CM_ "AUTOGENERATED FILE, DO NOT EDIT";

CM_ "hyundai_canfd.dbc starts here";
VERSION ""

NS_ :

BS_:

BU_: XXX CAMERA FRONT_RADAR ADRV APRK

BO_ 53 ACCELERATOR: 32 XXX
 SG_ CHECKSUM : 0|16@1+ (1,0) [0|65535] "" XXX
 SG_ COUNTER : 16|8@1+ (1,0) [0|255] "" XXX
 SG_ ACCELERATOR_PEDAL : 40|8@1+ (1,0) [0|255] "" XXX
 SG_ GEAR : 192|3@1+ (1,0) [0|7] "" XXX

BO_ 64 GEAR_ALT: 32 XXX
 SG_ CHECKSUM : 0|16@1+ (1,0) [0|65535] "" XXX
 SG_ COUNTER : 16|8@1+ (1,0) [0|255] "" XXX
 SG_ GEAR : 32|3@1+ (1,0) [0|7] "" XXX
 SG_ GEAR_STEP : 67|4@0+ (1,0) [0|15] "" XXX
 SG_ NEW_SIGNAL_4 : 68|4@1+ (1,0) [0|15] "" XXX
 SG_ NEW_SIGNAL_1 : 75|4@0+ (1,0) [0|15] "" XXX
 SG_ NEW_SIGNAL_3 : 76|4@1+ (1,0) [0|15] "" XXX

BO_ 69 GEAR: 24 XXX
 SG_ CHECKSUM : 0|16@1+ (1,0) [0|65535] "" XXX
 SG_ COUNTER : 16|8@1+ (1,0) [0|255] "" XXX
 SG_ GEAR : 44|3@1+ (1,0) [0|7] "" XXX
 SG_ RIGHT_PADDLE : 57|1@0+ (1,0) [0|1] "" XXX
 SG_ LEFT_PADDLE : 58|1@0+ (1,0) [0|1] "" XXX
 SG_ GEAR_STEP : 146|5@1+ (1,0) [0|31] "" XXX
 SG_ GEAR_STEP1 : 154|5@1+ (1,0) [0|31] "" XXX

BO_ 80 LKAS: 16 XXX
 SG_ CHECKSUM : 0|16@1+ (1,0) [0|65535] "" XXX
 SG_ COUNTER : 16|8@1+ (1,0) [0|255] "" XXX
 SG_ LKA_MODE : 24|3@1+ (1,0) [0|7] "" XXX
 SG_ LKA_ACTIVE : 27|2@1+ (1,0) [0|255] "" XXX
 SG_ LKA_WARNING : 32|1@1+ (1,0) [0|1] "" XXX
 SG_ LKA_ICON : 38|2@1+ (1,0) [0|255] "" XXX
 SG_ FCA_SYSWARN : 40|1@0+ (1,0) [0|1] "" XXX
 SG_ TORQUE_REQUEST : 41|11@1+ (1,-1024) [0|4095] "" XXX
 SG_ STEER_REQ : 52|1@1+ (1,0) [0|1] "" XXX
 SG_ LFA_BUTTON : 56|1@1+ (1,0) [0|255] "" XXX
 SG_ VALUE63 : 63|4@0+ (1,0) [0|15] "" XXX
 SG_ VALUE64 : 64|8@1+ (1,0) [0|255] "" XXX
 SG_ NEW_SIGNAL_1 : 75|4@0+ (1,0) [0|15] "" XXX
 SG_ LKAS_ANGLE_ACTIVE : 77|2@0+ (1,0) [0|3] "" XXX
 SG_ HAS_LANE_SAFETY : 80|1@0+ (1,0) [0|1] "" XXX
 SG_ LKAS_ANGLE_CMD : 82|14@1- (-0.1,0) [0|511] "" XXX
 SG_ LKAS_ANGLE_MAX_TORQUE : 96|8@1+ (1,0) [0|255] "" XXX
 SG_ DampingGain : 104|8@1+ (1,0) [0|255] "" XXX

BO_ 81 ADRV_0x51: 32 ADRV
 SG_ CHECKSUM : 0|16@1+ (1,0) [0|65535] "" XXX
 SG_ COUNTER : 16|8@1+ (1,0) [0|255] "" XXX

BO_ 96 ESP_STATUS: 32 XXX
 SG_ CHECKSUM : 0|16@1+ (1,0) [0|65535] "" XXX
 SG_ COUNTER : 16|8@1+ (1,0) [0|255] "" XXX
 SG_ TRACTION_AND_STABILITY_CONTROL : 42|3@1+ (1,0) [0|63] "" XXX
 SG_ BRAKE_PRESSURE : 128|11@1+ (1,0) [0|2047] "" XXX
 SG_ BRAKE_PRESSED : 148|1@1+ (1,0) [0|3] "" XXX
 SG_ AVH_Sta : 192|2@1+ (1,0) [0|3] "" XXX
 SG_ AVH_I_LAMP : 218|2@1+ (1,0) [0|3] "" XXX
 SG_ AVH_LAMP : 220|3@1+ (1,0) [0|7] "" XXX

BO_ 101 BRAKE: 32 XXX
 SG_ CHECKSUM : 0|16@1+ (1,0) [0|65535] "" XXX
 SG_ COUNTER : 16|8@1+ (1,0) [0|255] "" XXX
 SG_ BRAKE_LIGHT : 29|1@0+ (1,0) [0|1] "" XXX
 SG_ BRAKE_POSITION : 40|16@1- (1,0) [0|65535] "" XXX
 SG_ BRAKE_PRESSED : 57|1@1+ (1,0) [0|3] "" XXX

BO_ 112 GEAR_ALT_2: 32 XXX
 SG_ CHECKSUM : 0|16@1+ (1,0) [0|65535] "" XXX
 SG_ COUNTER : 16|8@1+ (1,0) [0|255] "" XXX
 SG_ GEAR : 60|3@1+ (1,0) [0|7] "" XXX

BO_ 147 CANFD_NAVI_PROFILE_093: 24 XXX
 SG_ PROLONG_VALUE : 64|32@1+ (1,0) [0|4294967295] "" XXX
 SG_ PROLONG_OFFSET : 96|13@1+ (1,0) [0|8191] "m" XXX
 SG_ PROLONG_CYCLIC_COUNTER : 109|2@1+ (1,0) [0|3] "" XXX
 SG_ PROLONG_UPDATE : 111|1@1+ (1,0) [0|1] "" XXX
 SG_ PROLONG_PATH_INDEX : 112|6@1+ (1,0) [0|63] "" XXX
 SG_ PROLONG_PROFILE_TYPE : 118|5@1+ (1,0) [0|31] "" XXX

BO_ 160 WHEEL_SPEEDS: 24 XXX
 SG_ CHECKSUM : 0|16@1+ (1,0) [0|65535] "" XXX
 SG_ COUNTER : 16|8@1+ (1,0) [0|255] "" XXX
 SG_ MOVING_FORWARD : 56|1@0+ (1,0) [0|1] "" XXX
 SG_ MOVING_BACKWARD : 57|1@0+ (1,0) [0|1] "" XXX
 SG_ MOVING_FORWARD2 : 58|1@0+ (1,0) [0|1] "" XXX
 SG_ MOVING_BACKWARD2 : 59|1@0+ (1,0) [0|1] "" XXX
 SG_ WHEEL_SPEED_1 : 64|16@1+ (0.03125,0) [0|65535] "kph" XXX
 SG_ WHEEL_SPEED_2 : 80|16@1+ (0.03125,0) [0|65535] "kph" XXX
 SG_ WHEEL_SPEED_3 : 96|16@1+ (0.03125,0) [0|65535] "kph" XXX
 SG_ WHEEL_SPEED_4 : 112|16@1+ (0.03125,0) [0|65535] "kph" XXX

BO_ 203 LFA_ALT: 24 ADRV
 SG_ CHECKSUM : 0|16@1+ (1,0) [0|65535] "" XXX
 SG_ COUNTER : 16|8@1+ (1,0) [0|255] "" XXX
 SG_ LKAS_ANGLE_ACTIVE : 29|2@0+ (1,0) [0|3] "" XXX
 SG_ LKAS_ANGLE_CMD : 32|14@1- (-0.1,0) [0|511] "" XXX
 SG_ LKAS_ANGLE_MAX_TORQUE : 55|8@0+ (1,0) [0|255] "" XXX

BO_ 234 MDPS: 24 XXX
 SG_ CHECKSUM : 0|16@1+ (1,0) [0|65535] "" XXX
 SG_ COUNTER : 16|8@1+ (1,0) [0|255] "" XXX
 SG_ NEW_SIGNAL_1 : 31|8@0+ (1,0) [0|255] "" XXX
 SG_ NEW_SIGNAL_2 : 39|8@0+ (1,0) [0|255] "" XXX
 SG_ NEW_SIGNAL_3 : 47|8@0+ (1,0) [0|255] "" XXX
 SG_ LKA_ACTIVE : 48|1@0+ (1,0) [0|16777215] "" XXX
 SG_ LKA_FAULT : 54|1@0+ (1,0) [0|1] "" XXX
 SG_ STEERING_OUT_TORQUE : 64|12@1+ (0.1,-204.8) [0|65535] "" XXX
 SG_ STEERING_COL_TORQUE : 80|13@1+ (1,-4095) [0|4095] "" XXX
 SG_ STEERING_ANGLE : 96|16@1- (-0.1,0) [0|255] "deg" XXX
 SG_ STEERING_ANGLE_2 : 128|16@1- (-0.1,0) [0|65535] "deg" XXX
 SG_ LFA2_ACTIVE : 145|2@0+ (1,0) [0|3] "" XXX
 SG_ LFA2_FAULT : 149|1@0+ (1,0) [0|1] "" XXX
 SG_ NEW_SIGNAL_4 : 159|8@0+ (1,0) [0|255] "" XXX
 SG_ NEW_SIGNAL_5 : 167|8@0+ (1,0) [0|255] "" XXX
 SG_ NEW_SIGNAL_6 : 175|8@0+ (1,0) [0|255] "" XXX

BO_ 256 ACCELERATOR_BRAKE_ALT: 32 XXX
 SG_ CHECKSUM : 0|16@1+ (1,0) [0|65535] "" XXX
 SG_ COUNTER : 16|8@1+ (1,0) [0|255] "" XXX
 SG_ BRAKE_PRESSED : 32|1@1+ (1,0) [0|1] "" XXX
 SG_ ACCELERATOR_PEDAL_PRESSED : 176|1@1+ (1,0) [0|1] "" XXX

BO_ 261 ACCELERATOR_ALT: 32 XXX
 SG_ CHECKSUM : 0|16@1+ (1,0) [0|65535] "" XXX
 SG_ COUNTER : 16|8@1+ (1,0) [0|255] "" XXX
 SG_ ACCELERATOR_PEDAL : 103|10@1+ (0.25,0) [0|1022] "" XXX

BO_ 267 CRUISE_BUTTONS_ALT2: 16 XXX
 SG_ CRUISE_BUTTONS : 83|4@0+ (1,0) [0|15] "" XXX
 SG_ LFA_BTN : 87|1@0+ (1,0) [0|1] "" XXX

BO_ 272 LKAS_ALT: 32 XXX
 SG_ CHECKSUM : 0|16@1+ (1,0) [0|65535] "" XXX
 SG_ COUNTER : 16|8@1+ (1,0) [0|255] "" XXX
 SG_ LKA_MODE : 24|3@1+ (1,0) [0|7] "" XXX
 SG_ LKA_ACTIVE : 27|2@1+ (1,0) [0|3] "" XXX
 SG_ LKA_WARNING : 32|1@1+ (1,0) [0|1] "" XXX
 SG_ LKA_ICON : 38|2@1+ (1,0) [0|3] "" XXX
 SG_ FCA_SYSWARN : 40|1@0+ (1,0) [0|1] "" XXX
 SG_ TORQUE_REQUEST : 41|11@1+ (1,-1024) [0|4095] "" XXX
 SG_ STEER_REQ : 52|1@1+ (1,0) [0|1] "" XXX
 SG_ LFA_BUTTON : 56|1@1+ (1,0) [0|1] "" XXX
 SG_ VALUE63 : 63|4@0+ (1,0) [0|15] "" XXX
 SG_ VALUE64 : 64|8@1+ (1,0) [0|255] "" XXX
 SG_ NEW_SIGNAL_1 : 75|4@0+ (1,0) [0|15] "" XXX
 SG_ LKAS_ANGLE_ACTIVE : 77|2@0+ (1,0) [0|3] "" XXX
 SG_ HAS_LANE_SAFETY : 80|1@0+ (1,0) [0|1] "" XXX
 SG_ LKAS_ANGLE_CMD : 82|14@1- (-0.1,0) [0|511] "" XXX
 SG_ LKAS_ANGLE_MAX_TORQUE : 96|8@1+ (1,0) [0|255] "" XXX
 SG_ DampingGain : 104|8@1+ (1,0) [0|255] "" XXX
 SG_ VALUE231 : 231|8@0+ (1,0) [0|255] "" XXX
 SG_ VALUE239 : 239|8@0+ (1,0) [0|255] "" XXX
 SG_ VALUE247 : 247|8@0+ (1,0) [0|255] "" XXX
 SG_ VALUE255 : 255|8@0+ (1,0) [0|255] "" XXX

BO_ 293 STEERING_SENSORS: 16 XXX
 SG_ CHECKSUM : 0|16@1+ (1,0) [0|65535] "" XXX
 SG_ COUNTER : 16|8@1+ (1,0) [0|255] "" XXX
 SG_ STEERING_ANGLE : 24|16@1- (-0.1,0) [0|255] "deg" XXX
 SG_ STEERING_RATE : 40|8@1+ (4,0) [0|1016] "deg/s" XXX

BO_ 298 LFA: 16 ADRV
 SG_ CHECKSUM : 0|16@1+ (1,0) [0|65535] "" XXX
 SG_ COUNTER : 16|8@1+ (1,0) [0|255] "" XXX
 SG_ LKA_MODE : 24|3@1+ (1,0) [0|7] "" XXX
 SG_ LKA_ACTIVE : 27|2@1+ (1,0) [0|3] "" XXX
 SG_ LKA_WARNING : 32|1@1+ (1,0) [0|1] "" XXX
 SG_ LKA_ICON : 38|2@1+ (1,0) [0|3] "" XXX
 SG_ FCA_SYSWARN : 40|1@0+ (1,0) [0|1] "" XXX
 SG_ TORQUE_REQUEST : 41|11@1+ (1,-1024) [0|4095] "" XXX
 SG_ STEER_REQ : 52|1@1+ (1,0) [0|1] "" XXX
 SG_ LFA_BUTTON : 56|1@1+ (1,0) [0|1] "" XXX
 SG_ VALUE63 : 63|4@0+ (1,0) [0|15] "" XXX
 SG_ VALUE64 : 64|8@1+ (1,0) [0|255] "" XXX
 SG_ NEW_SIGNAL_1 : 75|4@0+ (1,0) [0|15] "" XXX
 SG_ LKAS_ANGLE_ACTIVE : 77|2@0+ (1,0) [0|3] "" XXX
 SG_ HAS_LANE_SAFETY : 80|1@0+ (1,0) [0|1] "" XXX
 SG_ LKAS_ANGLE_CMD : 82|14@1- (-0.1,0) [0|511] "" XXX
 SG_ LKAS_ANGLE_MAX_TORQUE : 96|8@1+ (1,0) [0|255] "" XXX
 SG_ DampingGain : 104|8@1+ (1,0) [0|255] "" XXX
 SG_ VALUE231 : 231|8@0+ (1,0) [0|255] "" XXX
 SG_ VALUE239 : 239|8@0+ (1,0) [0|255] "" XXX
 SG_ VALUE247 : 247|8@0+ (1,0) [0|255] "" XXX
 SG_ VALUE255 : 255|8@0+ (1,0) [0|255] "" XXX

BO_ 304 GEAR_SHIFTER: 16 XXX
 SG_ CHECKSUM : 0|16@1+ (1,0) [0|65535] "" XXX
 SG_ COUNTER : 16|8@1+ (1,0) [0|255] "" XXX
 SG_ PARK_BUTTON : 32|2@1+ (1,0) [0|3] "" XXX
 SG_ KNOB_POSITION : 40|3@1+ (1,0) [0|3] "" XXX
 SG_ GEAR : 64|3@1+ (1,0) [0|7] "" XXX

BO_ 1079 TRAILER_STATUS: 8 XXX
 SG_ TRAILER_CONNECTED : 0|1@1+ (1,0) [0|1] "" XXX

BO_ 352 ADRV_0x160: 16 ADRV
 SG_ CHECKSUM : 0|16@1+ (1,0) [0|65535] "" XXX
 SG_ COUNTER : 16|8@1+ (1,0) [0|255] "" XXX
 SG_ AEB_SETTING : 24|2@1+ (1,0) [0|255] "" XXX
 SG_ NEW_SIGNAL_1 : 30|1@0+ (1,0) [0|1] "" XXX
 SG_ NEW_SIGNAL_4 : 31|1@0+ (1,0) [0|1] "" XXX
 SG_ NEW_SIGNAL_5 : 39|8@0+ (1,0) [0|255] "" XXX
 SG_ NEW_SIGNAL_6 : 47|8@0+ (1,0) [0|255] "" XXX
 SG_ NEW_SIGNAL_2 : 55|8@0+ (1,0) [0|255] "" XXX
 SG_ SET_ME_2 : 56|8@1+ (1,0) [0|1] "" XXX
 SG_ SET_ME_FF : 64|8@1+ (1,0) [0|255] "" XXX
 SG_ SET_ME_FC : 72|8@1+ (1,0) [0|255] "" XXX
 SG_ SET_ME_9 : 80|8@1+ (1,0) [0|255] "" XXX
 SG_ NEW_SIGNAL_3 : 95|8@0+ (1,0) [0|255] "" XXX
 SG_ NEW_SIGNAL_7 : 102|1@0+ (1,0) [0|1] "" XXX

BO_ 353 ADRV_0x161: 32 ADRV
 SG_ CHECKSUM : 0|16@1+ (1,0) [0|65535] "" XXX
 SG_ COUNTER : 16|8@1+ (1,0) [0|255] "" XXX
 SG_ FCA_ICON : 24|3@1+ (1,0) [0|7] "" XXX
 SG_ FCA_ALT_ICON : 27|3@1+ (1,0) [0|7] "" XXX
 SG_ LKA_ICON : 30|3@1+ (1,0) [0|3] "" XXX
 SG_ HBA_ICON : 33|3@1+ (1,0) [0|7] "" XXX
 SG_ FCA_IMAGE : 42|3@1+ (1,0) [0|7] "" XXX
 SG_ BCA_LEFT : 51|3@1+ (1,0) [0|7] "" XXX
 SG_ BCA_RIGHT : 54|3@1+ (1,0) [0|7] "" XXX
 SG_ LCA_LEFT_ARROW : 57|3@1+ (1,0) [0|7] "" XXX
 SG_ LCA_RIGHT_ARROW : 60|3@1+ (1,0) [0|7] "" XXX
 SG_ CENTERLINE : 64|2@1+ (1,0) [0|3] "" XXX
 SG_ TARGET : 66|3@1+ (1,0) [0|7] "" XXX
 SG_ TARGET_DISTANCE : 69|11@1+ (0.1,0) [0|204.7] "m" XXX
 SG_ LANELINE_LEFT : 80|4@1+ (1,0) [0|15] "" XXX
 SG_ LANELINE_LEFT_POSITION : 84|6@1+ (1,0) [0|15] "" XXX
 SG_ LANELINE_RIGHT : 90|4@1+ (1,0) [0|15] "" XXX
 SG_ LANELINE_RIGHT_POSITION : 94|6@1+ (1,0) [0|15] "" XXX
 SG_ LANELINE_CURVATURE : 100|4@1+ (1,0) [0|31] "" XXX
 SG_ LANELINE_CURVATURE_DIRECTION : 104|1@0+ (1,0) [0|1] "" XXX
 SG_ LANE_HIGHLIGHT : 105|4@1+ (1,0) [0|15] "" XXX
 SG_ LANE_HIGHLIGHT_DISTANCE : 109|11@1+ (0.1,0) [0|204.7] "m" XXX
 SG_ LANE_LEFT : 120|3@1+ (1,0) [0|7] "" XXX
 SG_ LANE_RIGHT : 123|3@1+ (1,0) [0|7] "" XXX
 SG_ LANE_ZOOM : 126|2@1+ (1,0) [0|3] "" XXX
 SG_ ALERTS_1 : 128|6@1+ (1,0) [0|63] "" XXX
 SG_ ALERTS_2 : 134|5@1+ (1,0) [0|31] "" XXX
 SG_ ALERTS_3 : 139|5@1+ (1,0) [0|31] "" XXX
 SG_ ALERTS_4 : 144|8@1+ (1,0) [0|255] "" XXX
 SG_ ALERTS_5 : 152|5@1+ (1,0) [0|31] "" XXX
 SG_ MUTE : 157|3@1+ (1,0) [0|7] "" XXX
 SG_ SOUNDS_1 : 160|4@1+ (1,0) [0|3] "" XXX
 SG_ SOUNDS_2 : 164|4@1+ (1,0) [0|3] "" XXX
 SG_ SOUNDS_3 : 168|4@1+ (1,0) [0|15] "" XXX
 SG_ SOUNDS_4 : 172|3@1+ (1,0) [0|7] "" XXX
 SG_ SETSPEED_HUD : 181|3@1+ (1,0) [0|7] "" XXX
 SG_ DISTANCE_LEAD : 184|5@1+ (1,0) [0|31] "" XXX
 SG_ DISTANCE_CAR : 189|3@1+ (1,0) [0|7] "" XXX
 SG_ DISTANCE_SPACING : 192|4@1+ (1,0) [0|15] "" XXX
 SG_ DISTANCE : 196|4@1+ (1,0) [0|7] "" XXX
 SG_ vSetDis : 200|8@1+ (1,0) [0|255] "" XXX
 SG_ SETSPEED : 208|4@1+ (1,0) [0|7] "" XXX
 SG_ HDA_ICON : 212|3@1+ (1,0) [0|7] "" XXX
 SG_ SLA_ICON : 216|4@1+ (1,0) [0|15] "" XXX
 SG_ NAV_ICON : 220|3@1+ (1,0) [0|7] "" XXX
 SG_ LFA_ICON : 224|3@1+ (1,0) [0|7] "" XXX
 SG_ LCA_LEFT_ICON : 228|3@1+ (1,0) [0|7] "" XXX
 SG_ LCA_RIGHT_ICON : 232|3@1+ (1,0) [0|7] "" XXX
 SG_ BACKGROUND : 236|4@1+ (1,0) [0|15] "" XXX
 SG_ DAW_ICON : 240|3@1+ (1,0) [0|7] "" XXX
 SG_ CAR_CIRCLE : 243|3@1+ (1,0) [0|7] "" XXX

BO_ 354 CCNC_0x162: 32 CCNC
 SG_ CHECKSUM : 0|16@1+ (1,0) [0|65535] "" XXX
 SG_ COUNTER : 16|8@1+ (1,0) [0|255] "" XXX
 SG_ COUNTRY : 24|4@1+ (1,0) [0|7] "" XXX
 SG_ SPEEDLIMIT_FLASH : 28|4@1+ (1,0) [0|15] "" XXX
 SG_ SPEEDLIMIT : 32|8@1+ (1,0) [0|255] "" XXX
 SG_ SIGNS : 40|8@1+ (1,0) [0|15] "" XXX
 SG_ SPEEDLIMIT_WEATHER : 48|4@1+ (1,0) [0|15] "" XXX
 SG_ VIBRATE : 52|1@0+ (1,0) [0|1] "" XXX
 SG_ FF_DETECT : 64|5@1+ (1,0) [0|31] "" XXX
 SG_ FF_DISTANCE : 69|11@1+ (0.1,0) [0|204.7] "m" XXX
 SG_ FF_LATERAL : 80|7@1+ (0.1,0) [0|127] "m" XXX
 SG_ FF_DETECT_ALT : 88|5@1+ (1,0) [0|31] "" XXX
 SG_ FF_DISTANCE_ALT : 93|11@1+ (0.1,0) [0|204.7] "m" XXX
 SG_ FF_LATERAL_ALT : 104|7@1+ (0.1,0) [0|127] "m" XXX
 SG_ LF_DETECT : 112|5@1+ (1,0) [0|31] "" XXX
 SG_ LF_DETECT_DISTANCE : 117|11@1+ (0.1,0) [0|204.7] "m" XXX
 SG_ LF_DETECT_LATERAL : 128|7@1+ (0.1,0) [0|127] "m" XXX
 SG_ RF_DETECT : 136|5@1+ (1,0) [0|31] "" XXX
 SG_ RF_DETECT_DISTANCE : 141|11@1+ (0.1,0) [0|204.7] "m" XXX
 SG_ RF_DETECT_LATERAL : 152|7@1+ (0.1,0) [0|127] "m" XXX
 SG_ LR_DETECT : 163|5@1+ (1,0) [0|31] "" XXX
 SG_ LR_DETECT_DISTANCE : 175|8@0+ (0.1,0) [0|255] "" XXX
 SG_ LR_DETECT_LATERAL : 176|7@1+ (0.1,0) [0|127] "" XXX
 SG_ RR_DETECT : 192|5@1+ (1,0) [0|31] "" XXX
 SG_ RR_DETECT_DISTANCE : 197|8@1+ (0.1,0) [0|255] "" XXX
 SG_ RR_DETECT_LATERAL : 205|7@1+ (0.1,0) [0|127] "" XXX
 SG_ FAULT_FSS : 213|3@1+ (1,0) [0|7] "" XXX
 SG_ FAULT_FCA : 216|3@1+ (1,0) [0|7] "" XXX
 SG_ FAULT_LSS : 219|3@1+ (1,0) [0|7] "" XXX
 SG_ FAULT_SLA : 222|3@1+ (1,0) [0|7] "" XXX
 SG_ FAULT_DAW : 225|3@1+ (1,0) [0|7] "" XXX
 SG_ FAULT_HBA : 228|3@1+ (1,0) [0|7] "" XXX
 SG_ FAULT_SCC : 231|3@1+ (1,0) [0|7] "" XXX
 SG_ FAULT_LFA : 234|3@1+ (1,0) [0|7] "" XXX
 SG_ FAULT_HDA : 237|3@1+ (1,0) [0|7] "" XXX
 SG_ FAULT_LCA : 240|3@1+ (1,0) [0|7] "" XXX
 SG_ FAULT_HDP : 243|3@1+ (1,0) [0|7] "" XXX
 SG_ FAULT_DAS : 246|3@1+ (1,0) [0|7] "" XXX
 SG_ FAULT_ESS : 249|3@1+ (1,0) [0|7] "" XXX

BO_ 357 SPAS1: 24 APRK
 SG_ CHECKSUM : 0|16@1+ (1,0) [0|65535] "" XXX
 SG_ COUNTER : 16|8@1+ (1,0) [0|0] "" XXX
 SG_ NEW_SIGNAL_2 : 90|3@1+ (1,0) [0|0] "" XXX
 SG_ NEW_SIGNAL_1 : 96|16@1- (0.1,0) [0|0] "" XXX

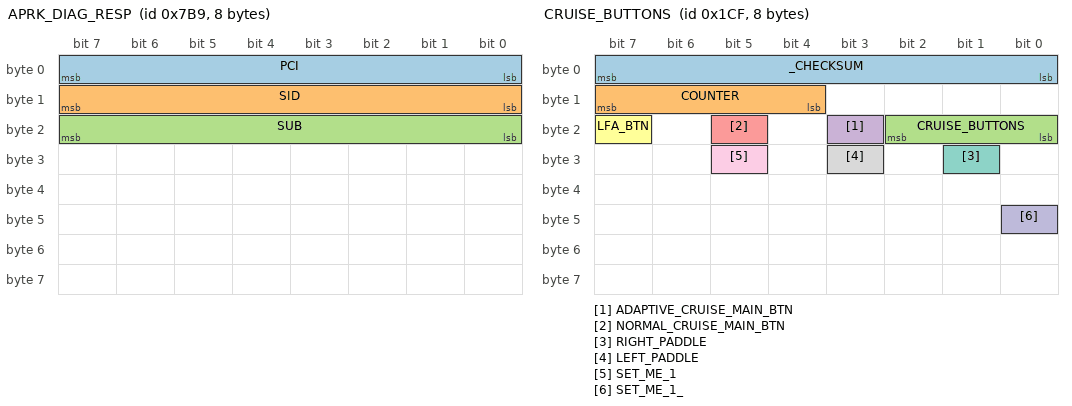
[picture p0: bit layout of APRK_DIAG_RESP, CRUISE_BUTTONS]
BO_ 1977 APRK_DIAG_RESP: 8 APRK
 SG_ PCI : 0|8@1+ (1,0) [0|255] "" XXX
 SG_ SID : 8|8@1+ (1,0) [0|255] "" XXX
 SG_ SUB : 16|8@1+ (1,0) [0|255] "" XXX

BO_ 1024 SVM_STATUS_400: 8 XXX
 SG_ BYTE3 : 24|8@1+ (1,0) [0|255] "" XXX
 SG_ BVM_VIEW : 32|8@1+ (1,0) [0|255] "" XXX

BO_ 362 SPAS2: 32 APRK
 SG_ CHECKSUM : 0|16@1+ (1,0) [0|65535] "" XXX
 SG_ COUNTER : 16|8@1+ (1,0) [0|0] "" XXX
 SG_ BLINKER_CONTROL : 133|3@1+ (1,0) [0|0] "" XXX
 SG_ BYTE3 : 24|8@1+ (1,0) [0|255] "" XXX
 SG_ BYTE4 : 32|8@1+ (1,0) [0|255] "" XXX
 SG_ BYTE10 : 80|8@1+ (1,0) [0|255] "" XXX
 SG_ BYTE11 : 88|8@1+ (1,0) [0|255] "" XXX
 SG_ BYTE12 : 96|8@1+ (1,0) [0|255] "" XXX
 SG_ BYTE13 : 104|8@1+ (1,0) [0|255] "" XXX
 SG_ BYTE14 : 112|8@1+ (1,0) [0|255] "" XXX
 SG_ BYTE15 : 120|8@1+ (1,0) [0|255] "" XXX
 SG_ BYTE20 : 160|8@1+ (1,0) [0|255] "" XXX

BO_ 373 TCS: 24 XXX
 SG_ CHECKSUM : 0|16@1+ (1,0) [0|65535] "" XXX
 SG_ COUNTER : 16|8@1+ (1,0) [0|255] "" XXX
 SG_ NEW_SIGNAL_4 : 24|7@1+ (1,0) [0|127] "" XXX
 SG_ NEW_SIGNAL_9 : 31|1@0+ (1,0) [0|1] "" XXX
 SG_ aBasis : 32|11@1+ (0.01,-10.23) [0|7] "m/s^2" XXX
 SG_ NEW_SIGNAL_1 : 47|5@0+ (1,0) [0|31] "" XXX
 SG_ ACCEL_REF_ACC : 48|11@1- (1,0) [0|1023] "" XXX
 SG_ NEW_SIGNAL_2 : 63|5@0+ (1,0) [0|31] "" XXX
 SG_ SCC_OptTyp : 64|2@1+ (1,0) [0|0] "" AWD,EMS,FR_CMR,HCU,H_U_MM,TCU,VCU,vBDM
 SG_ ACCEnable : 67|2@0+ (1,0) [0|3] "" XXX
 SG_ ACC_REQ : 68|1@0+ (1,0) [0|1] "" XXX
 SG_ NEW_SIGNAL_3 : 69|1@0+ (1,0) [0|1] "" XXX
 SG_ SCC_ReqLimSta : 70|2@1+ (1,0) [0|0] "" ADAS_DRV,AWD,Dummy,EMS,FR_CMR,H_U_MM,TCU,vBDM
 SG_ ESC_StdStillVal : 72|2@1+ (1,0) [0|3] "" ADAS_DRV,AWD,Dummy,EMS,FR_CMR,H_U_MM,TCU,vBDM
 SG_ BrakeLight : 74|2@1+ (1,0) [0|3] "" XXX
 SG_ ESC_DclEnblReq : 76|2@1+ (1,0) [0|3] "" AWD,Dummy,EMS,FR_CMR,H_U_MM,TCU,vBDM
 SG_ NEW_SIGNAL_5 : 79|2@0+ (1,0) [0|3] "" XXX
 SG_ NEW_SIGNAL_21 : 80|1@0+ (1,0) [0|1] "" XXX
 SG_ DriverBraking : 81|1@0+ (1,0) [0|1] "" XXX
 SG_ NEW_SIGNAL_20 : 82|1@0+ (1,0) [0|1] "" XXX
 SG_ NEW_SIGNAL_11 : 83|1@0+ (1,0) [0|1] "" XXX
 SG_ DriverBrakingLowSens : 84|1@1+ (1,0) [0|1] "" XXX
 SG_ NEW_SIGNAL_10 : 85|1@0+ (1,0) [0|1] "" XXX
 SG_ ESC_PrkBrkActvSta : 86|2@1+ (1,0) [0|3] "" ADAS_DRV,AWD,Dummy,EMS,FR_CMR,H_U_MM,RR_C_RDR,TCU,vBDM
 SG_ NEW_SIGNAL_12 : 95|8@0+ (1,0) [0|255] "" XXX
 SG_ FCA_EquipSta : 96|2@1+ (1,0) [0|3] "" ADAS_DRV,FR_CMR,H_U_MM,vBDM
 SG_ FCA_AvlblSta : 98|2@1+ (1,0) [0|3] "" ADAS_DRV,AFCU_DRV,CLU,Dummy,FR_CMR,H_U_MM,vBDM
 SG_ NEW_SIGNAL_13 : 103|4@0+ (1,0) [0|15] "" XXX
 SG_ NEW_SIGNAL_14 : 111|8@0+ (1,0) [0|255] "" XXX
 SG_ NEW_SIGNAL_15 : 119|8@0+ (1,0) [0|255] "" XXX
 SG_ NEW_SIGNAL_16 : 127|8@0+ (1,0) [0|255] "" XXX
 SG_ NEW_SIGNAL_6 : 128|4@1+ (1,0) [0|15] "" XXX
 SG_ NEW_SIGNAL_17 : 133|2@0+ (1,0) [0|3] "" XXX
 SG_ NEW_SIGNAL_7 : 135|2@0+ (1,0) [0|3] "" XXX
 SG_ PROBABLY_EQUIP : 136|2@1+ (1,0) [0|3] "" XXX
 SG_ NEW_SIGNAL_18 : 143|6@0+ (1,0) [0|63] "" XXX
 SG_ NEW_SIGNAL_19 : 151|8@0+ (1,0) [0|255] "" XXX
 SG_ NEW_SIGNAL_8 : 183|16@0+ (1,0) [0|65535] "" XXX

BO_ 384 CAM_0x180: 32 CAMERA
 SG_ CHECKSUM : 0|16@1+ (1,0) [0|65535] "" XXX
 SG_ COUNTER : 16|8@1+ (1,0) [0|255] "" XXX

BO_ 385 CAM_0x181: 32 CAMERA
 SG_ CHECKSUM : 0|16@1+ (1,0) [0|65535] "" XXX
 SG_ COUNTER : 16|8@1+ (1,0) [0|255] "" XXX

BO_ 386 CAM_0x182: 32 CAMERA
 SG_ CHECKSUM : 0|16@1+ (1,0) [0|65535] "" XXX
 SG_ COUNTER : 16|8@1+ (1,0) [0|255] "" XXX

BO_ 387 CAM_0x183: 32 CAMERA
 SG_ CHECKSUM : 0|16@1+ (1,0) [0|65535] "" XXX
 SG_ COUNTER : 16|8@1+ (1,0) [0|255] "" XXX

BO_ 388 CAM_0x184: 32 CAMERA
 SG_ CHECKSUM : 0|16@1+ (1,0) [0|65535] "" XXX
 SG_ COUNTER : 16|8@1+ (1,0) [0|255] "" XXX

BO_ 389 CAM_0x185: 8 CAMERA
 SG_ CHECKSUM : 0|16@1+ (1,0) [0|65535] "" XXX
 SG_ COUNTER : 16|8@1+ (1,0) [0|255] "" XXX

BO_ 416 SCC_CONTROL: 32 ADRV
 SG_ CHECKSUM : 0|16@1+ (1,0) [0|65535] "" XXX
 SG_ COUNTER : 16|8@1+ (1,0) [0|255] "" XXX
 SG_ ACC_ObjDist : 24|11@1+ (0.1,0) [0|204.7] "m" XXX
 SG_ ACC_ObjRelSpd : 35|12@1+ (0.1,-170) [-16.4|34.7] "m/s" XXX
 SG_ ACC_ObjLatPos : 47|9@1- (0.1,-20) [0|511] "" XXX
 SG_ ZEROS_7 : 63|8@0+ (1,0) [0|255] "" XXX
 SG_ SysFailState : 64|2@1+ (1,0) [0|3] "" XXX
 SG_ MainMode_ACC : 66|1@1+ (1,0) [0|1] "" XXX
 SG_ ACCMode : 68|3@1+ (1,0) [0|7] "" XXX
 SG_ TakeOverReq : 73|2@0+ (1,0) [0|3] "" XXX
 SG_ InfoDisplay : 74|3@1+ (1,0) [0|7] "" XXX
 SG_ DriverAlert : 77|2@1+ (1,0) [0|3] "" XXX
 SG_ ObjDistLevel : 80|8@1+ (1,0) [0|255] "" XXX
 SG_ DISTANCE_SETTING : 88|4@1+ (1,0) [0|15] "" XXX
 SG_ VSetDis : 103|8@0+ (1,0) [0|255] "km/h or mph" XXX
 SG_ NSCCOper : 104|2@1+ (1,0) [0|3] "" XXX
 SG_ NSCCOnOff : 106|2@1+ (1,0) [0|3] "" XXX
 SG_ HUD_LEAD_INFO : 108|3@1+ (1,0) [0|7] "" XXX
 SG_ DriveMode : 112|3@1+ (1,0) [0|7] "" XXX
 SG_ aReqValue : 128|11@1+ (0.01,-10.23) [-10.23|10.24] "m/s^2" XXX
 SG_ aReqRaw : 140|11@1+ (0.01,-10.23) [-10.23|10.24] "m/s^2" XXX
 SG_ JerkUpperLimit : 158|7@0+ (0.1,0) [0|0] "" XXX
 SG_ JerkLowerLimit : 166|7@0+ (0.1,0) [0|12.7] "m/s^3" XXX
 SG_ AccelLimitBandUpper : 173|6@0+ (0.02,0) [0|63] "" XXX
 SG_ AccelLimitBandLower : 181|6@0+ (0.02,0) [0|63] "" XXX
 SG_ StopReq : 185|2@0+ (1,0) [0|3] "" XXX
 SG_ CRUSE_INFO_SET_2 : 189|2@0+ (1,0) [0|3] "" XXX
 SG_ TARGET_DISTANCE : 192|11@1+ (0.1,0) [0|204.7] "m" XXX
 SG_ ZEROS_2 : 207|5@0+ (1,0) [0|63] "" XXX
 SG_ ZEROS : 215|48@0+ (1,0) [0|281474976710655] "" XXX

BO_ 426 CRUISE_BUTTONS_ALT: 16 XXX
 SG_ CHECKSUM : 0|16@1+ (1,0) [0|65535] "" XXX
 SG_ COUNTER : 16|8@1+ (1,0) [0|255] "" XXX
 SG_ NEW_SIGNAL_1 : 24|4@1+ (1,0) [0|15] "" XXX
 SG_ SET_ME_1 : 28|2@1+ (1,0) [0|3] "" XXX
 SG_ DISTANCE_UNIT : 30|1@1+ (1,0) [0|1] "" XXX
 SG_ NEW_SIGNAL_2 : 31|3@1+ (1,0) [0|7] "" XXX
 SG_ ADAPTIVE_CRUISE_MAIN_BTN : 34|1@1+ (1,0) [0|1] "" XXX
 SG_ NEW_SIGNAL_3 : 35|1@1+ (1,0) [0|1] "" XXX
 SG_ CRUISE_BUTTONS : 36|3@1+ (1,0) [0|4] "" XXX
 SG_ LFA_BTN : 39|1@1+ (1,0) [0|1] "" XXX
 SG_ NEW_SIGNAL_4 : 40|1@1+ (1,0) [0|1] "" XXX
 SG_ NORMAL_CRUISE_MAIN_BTN : 41|1@1+ (1,0) [0|1] "" XXX
 SG_ NEW_SIGNAL_5 : 42|2@1+ (1,0) [0|3] "" XXX
 SG_ SET_ME_2 : 44|3@1+ (1,0) [0|7] "" XXX
 SG_ NEW_SIGNAL_6 : 47|1@1+ (1,0) [0|1] "" XXX
 SG_ BYTE6 : 48|8@1+ (1,0) [0|255] "" XXX
 SG_ BYTE7 : 56|8@1+ (1,0) [0|255] "" XXX
 SG_ CLU_SPEED : 64|8@1+ (1,0) [0|255] "" XXX
 SG_ BYTE9 : 72|8@1+ (1,0) [0|255] "" XXX
 SG_ BYTE10 : 80|8@1+ (1,0) [0|255] "" XXX
 SG_ BYTE11 : 88|8@1+ (1,0) [0|255] "" XXX
 SG_ BYTE12 : 96|8@1+ (1,0) [0|255] "" XXX
 SG_ BYTE13 : 104|8@1+ (1,0) [0|255] "" XXX
 SG_ BYTE14 : 112|8@1+ (1,0) [0|255] "" XXX
 SG_ BYTE15 : 120|8@1+ (1,0) [0|255] "" XXX

BO_ 437 CCNC_0x1B5: 32 CCNC
 SG_ CHECKSUM : 0|16@1+ (1,0) [0|65535] "" XXX
 SG_ COUNTER : 16|8@1+ (1,0) [0|255] "" XXX
 SG_ LEFT_QUAL : 24|3@1+ (1,0) [0|7] "" XXX
 SG_ LEFT_LDW : 27|2@1+ (1,0) [0|3] "" XXX
 SG_ LEFT_POSITION : 29|14@1- (0.0039625,0) [-32.4608|32.4568375] "m" XXX
 SG_ LEFT_HEADING : 43|10@1- (0.000976563,0) [-0.500000256|0.499023693] "rad" XXX
 SG_ LEFT_CURVATURE : 64|16@1- (1e-06,0) [-0.032768|0.032767] "1/m" XXX
 SG_ LEFT_CURVATURE_DERIVATIVE : 80|16@1- (4e-09,0) [-0.000131072|0.000131068] "1/m2" XXX
 SG_ RIGHT_QUAL : 96|3@1+ (1,0) [0|7] "" XXX
 SG_ RIGHT_LDW : 99|2@1+ (1,0) [0|3] "" XXX
 SG_ RIGHT_POSITION : 101|14@1- (0.0039625,0) [-32.4608|32.4568375] "m" XXX
 SG_ RIGHT_HEADING : 115|10@1- (0.000976563,0) [-0.500000256|0.499023693] "rad" XXX
 SG_ RIGHT_CURVATURE : 128|16@1- (1e-06,0) [-0.032768|0.032767] "1/m" XXX
 SG_ RIGHT_CURVATURE_DERIVATIVE : 144|16@1- (4e-09,0) [-0.000131072|0.000131068] "1/m2" XXX
 SG_ LEAD : 192|7@1+ (1,0) [0|127] "" XXX
 SG_ LEAD_SPEED : 200|12@1+ (0.05,-100) [-100|104.75] "m/s" XXX
 SG_ LEAD_DISTANCE : 212|12@1+ (0.05,0) [0|204.75] "m" XXX

BO_ 438 CAM_0x1b6: 32 CAMERA
 SG_ CHECKSUM : 0|16@1+ (1,0) [0|65535] "" XXX
 SG_ COUNTER : 16|8@1+ (1,0) [0|255] "" XXX

BO_ 439 CAM_0x1b7: 32 CAMERA
 SG_ CHECKSUM : 0|16@1+ (1,0) [0|65535] "" XXX
 SG_ COUNTER : 16|8@1+ (1,0) [0|255] "" XXX

BO_ 440 CAM_0x1b8: 32 CAMERA
 SG_ CHECKSUM : 0|16@1+ (1,0) [0|65535] "" XXX
 SG_ COUNTER : 16|8@1+ (1,0) [0|255] "" XXX

BO_ 441 CAM_0x1b9: 32 CAMERA
 SG_ CHECKSUM : 0|16@1+ (1,0) [0|65535] "" XXX
 SG_ COUNTER : 16|8@1+ (1,0) [0|255] "" XXX

BO_ 442 BLINDSPOTS_REAR_CORNERS: 24 XXX
 SG_ CHECKSUM : 0|16@1+ (1,0) [0|65535] "" XXX
 SG_ COUNTER : 16|8@1+ (1,0) [0|255] "" XXX
 SG_ LEFT_BLOCKED : 24|1@0+ (1,0) [0|1] "" XXX
 SG_ INDICATOR_LEFT_TWO : 31|2@0+ (1,0) [0|3] "" XXX
 SG_ INDICATOR_RIGHT_TWO : 32|2@1+ (1,0) [0|3] "" XXX
 SG_ FL_INDICATOR : 46|6@0+ (1,0) [0|1] "" XXX
 SG_ FR_INDICATOR : 54|6@0+ (1,0) [0|63] "" XXX
 SG_ RIGHT_BLOCKED : 64|1@0+ (1,0) [0|1] "" XXX
 SG_ COLLISION_AVOIDANCE_ACTIVE : 68|1@0+ (1,0) [0|1] "" XXX
 SG_ INDICATOR_LEFT_THREE : 128|1@0+ (1,0) [0|1] "" XXX
 SG_ INDICATOR_RIGHT_THREE : 130|1@0+ (1,0) [0|1] "" XXX
 SG_ INDICATOR_LEFT_FOUR : 138|1@0+ (1,0) [0|1] "" XXX
 SG_ INDICATOR_RIGHT_FOUR : 141|1@0+ (1,0) [0|1] "" XXX

BO_ 463 CRUISE_BUTTONS: 8 XXX
 SG_ _CHECKSUM : 0|8@1+ (1,0) [0|65535] "" XXX
 SG_ COUNTER : 12|4@1+ (1,0) [0|255] "" XXX
 SG_ CRUISE_BUTTONS : 16|3@1+ (1,0) [0|3] "" XXX
 SG_ ADAPTIVE_CRUISE_MAIN_BTN : 19|1@1+ (1,0) [0|1] "" XXX
 SG_ NORMAL_CRUISE_MAIN_BTN : 21|1@1+ (1,0) [0|1] "" XXX
 SG_ LFA_BTN : 23|1@1+ (1,0) [0|1] "" XXX
 SG_ RIGHT_PADDLE : 25|1@1+ (1,0) [0|1] "" XXX
 SG_ LEFT_PADDLE : 27|1@1+ (1,0) [0|1] "" XXX
 SG_ SET_ME_1 : 29|1@1+ (1,0) [0|1] "" XXX
 SG_ SET_ME_1_ : 40|1@0+ (1,0) [0|1] "" XXX

BO_ 474 ADRV_0x1da: 32 ADRV
 SG_ CHECKSUM : 0|16@1+ (1,0) [0|65535] "" XXX
 SG_ COUNTER : 16|8@1+ (1,0) [0|255] "" XXX
 SG_ SET_ME_22 : 31|8@0+ (1,0) [0|255] "" XXX
 SG_ SET_ME_41 : 47|8@0+ (1,0) [0|255] "" XXX

BO_ 480 LFAHDA_CLUSTER: 16 FR_CMR
 SG_ CHECKSUM : 0|16@1+ (1,0) [0|65535] "" XXX
 SG_ COUNTER : 16|8@1+ (1,0) [0|255] "" XXX
 SG_ HDA_OptUsmSta : 24|3@1+ (1,0) [0|0] "" CGW
 SG_ LFA_OptUsmSta : 27|3@1+ (1,0) [0|0] "" CGW
 SG_ HDA_CntrlModSta : 30|2@1+ (1,0) [0|0] "" CGW
 SG_ HDA_InfoPUDis : 32|3@1+ (1,0) [0|0] "" CGW
 SG_ HDA_AutoSetSpdSta : 35|2@1+ (1,0) [0|0] "" CGW
 SG_ HDA_AutoSetSpdUpdtSta : 37|2@1+ (1,0) [0|0] "" CGW
 SG_ HDA_AutoSetSpdVal : 39|8@1+ (1,0) [0|0] "km/h" CGW
 SG_ HDA_LFA_SymSta : 47|2@1+ (1,0) [0|0] "" CGW
 SG_ HDA_LFA_WrnSnd : 49|2@1+ (1,0) [0|0] "" Dummy
 SG_ HDA_InfoPUDis1 : 51|3@1+ (1,0) [0|7] "" CLU,CGW
 SG_ HDA_TDMRMDclReq : 54|2@1+ (1,0) [0|3] "" Dummy

BO_ 485 BLINDSPOTS_FRONT_CORNER_1: 16 XXX
 SG_ CHECKSUM : 0|16@1+ (1,0) [0|65535] "" XXX
 SG_ COUNTER : 16|8@1+ (1,0) [0|255] "" XXX
 SG_ REVERSING : 24|1@0+ (1,0) [0|1] "" XXX
 SG_ NEW_SIGNAL_5 : 31|2@0+ (1,0) [0|3] "" XXX
 SG_ NEW_SIGNAL_7 : 32|2@1+ (1,0) [0|3] "" XXX
 SG_ NEW_SIGNAL_8 : 47|8@0+ (1,0) [0|255] "" XXX
 SG_ NEW_SIGNAL_9 : 55|8@0+ (1,0) [0|255] "" XXX
 SG_ NEW_SIGNAL_4 : 80|1@0+ (1,0) [0|1] "" XXX
 SG_ NEW_SIGNAL_3 : 88|1@0+ (1,0) [0|1] "" XXX
 SG_ NEW_SIGNAL_2 : 96|1@0+ (1,0) [0|1] "" XXX
 SG_ NEW_SIGNAL_1 : 108|2@0+ (1,0) [0|3] "" XXX

BO_ 490 ADRV_0x1ea: 32 ADRV
 SG_ CHECKSUM : 0|16@1+ (1,0) [0|65535] "" XXX
 SG_ COUNTER : 16|8@1+ (1,0) [0|255] "" XXX
 SG_ NEW_SIGNAL_4 : 25|2@0+ (1,0) [0|3] "" XXX
 SG_ NEW_SIGNAL_3 : 26|1@0+ (1,0) [0|1] "" XXX
 SG_ NEW_SIGNAL_2 : 27|1@0+ (1,0) [0|1] "" XXX
 SG_ NEW_SIGNAL_1 : 28|1@0+ (1,0) [0|1] "" XXX
 SG_ LEFT_BLINK_HOLD : 29|1@0+ (1,0) [0|1] "" XXX
 SG_ RIGHT_BLINK_HOLD : 30|1@0+ (1,0) [0|1] "" XXX
 SG_ NEW_SIGNAL_5 : 31|1@0+ (1,0) [0|1] "" XXX
 SG_ HDA_MODE2 : 32|3@1+ (1,0) [0|3] "" XXX
 SG_ LANE_LEFT : 36|2@0+ (1,0) [0|3] "" XXX
 SG_ NEW_SIGNAL_6 : 39|3@0+ (1,0) [0|7] "" XXX
 SG_ LANE_RIGHT : 41|2@0+ (1,0) [0|3] "" XXX
 SG_ LANE_CHANGING : 45|3@0+ (1,0) [0|1] "" XXX
 SG_ LF_DETECT_DISTANCE : 46|11@1+ (0.1,0) [0|2047] "" XXX
 SG_ LF_DETECT_LATERAL : 70|7@0+ (0.1,0) [0|127] "" XXX
 SG_ LF_DETECT : 74|3@0+ (1,0) [0|7] "" XXX
 SG_ RF_DETECT_DISTANCE : 75|11@1+ (0.1,0) [0|2047] "" XXX
 SG_ RF_DETECT_LATERAL : 94|7@0+ (0.1,0) [0|127] "" XXX
 SG_ RF_DETECT : 98|3@0+ (1,0) [0|7] "" XXX
 SG_ SET_ME_FF : 120|8@1+ (1,0) [0|255] "" XXX
 SG_ LR_DETECT_DISTANCE : 139|8@1+ (0.1,0) [0|511] "m" XXX
 SG_ LR_DETECT_LATERAL : 152|6@1+ (0.1,0) [0|63] "" XXX
 SG_ LR_DETECT : 162|3@0+ (1,0) [0|1] "" XXX
 SG_ RR_DETECT_DISTANCE : 163|8@1+ (0.1,0) [0|511] "m" XXX
 SG_ RR_DETECT_LATERAL : 172|6@1+ (0.1,0) [0|63] "" XXX
 SG_ RR_DETECT : 186|3@0+ (1,0) [0|1] "" XXX
 SG_ AUTOLANECHANGE_MSG : 207|4@0+ (1,0) [0|3] "" XXX
 SG_ LANELINE_CURVATURE : 208|4@1+ (1,0) [0|31] "" XXX
 SG_ LANELINE_CURVATURE_DIRECTION : 212|1@0+ (1,0) [0|1] "" XXX
 SG_ LANELINE_LEFT_POSITION : 239|8@0+ (1,0) [0|255] "" XXX
 SG_ LANELINE_RIGHT_POSITION : 247|8@0+ (1,0) [0|255] "" XXX
 SG_ NEW_SIGNAL_7 : 248|1@0+ (1,0) [0|1] "" XXX

BO_ 506 CLUSTER_SPEED_LIMIT: 32 CAM
 SG_ SPEED_LIMIT_1 : 39|7@0+ (1,0) [0|255] "" XXX
 SG_ SPEED_LIMIT_2 : 47|7@0+ (1,0) [0|255] "" XXX
 SG_ SECONDARY_LIMIT_1 : 79|8@0+ (1,0) [0|127] "" XXX
 SG_ SECONDARY_LIMIT_2 : 103|8@0+ (1,0) [0|127] "" XXX
 SG_ SPEED_LIMIT_3 : 119|8@0+ (1,0) [0|255] "" XXX
 SG_ ARROW_DOWN : 120|1@0+ (1,0) [0|1] "" XXX
 SG_ ARROW_UP : 121|1@0+ (1,0) [0|1] "" XXX
 SG_ NEW_SIGNAL_2 : 122|3@1+ (1,0) [0|7] "" XXX
 SG_ SPEED_CHANGE_BLINKING : 129|1@1+ (1,0) [0|3] "" XXX
 SG_ CHIME_1 : 133|1@0+ (1,0) [0|1] "" XXX
 SG_ NEW_SIGNAL_4 : 143|8@0+ (1,0) [0|255] "" XXX
 SG_ NEW_SIGNAL_3 : 146|3@0+ (1,0) [0|7] "" XXX
 SG_ NEW_SIGNAL_1 : 147|7@1+ (1,0) [0|127] "" XXX
 SG_ SCHOOL_ZONE : 155|1@0+ (1,0) [0|1] "" XXX
 SG_ SPEED_LIMIT_4 : 215|8@0+ (1,0) [0|255] "" XXX
 SG_ NEW_SIGNAL_5 : 223|8@0+ (1,0) [0|255] "" XXX

BO_ 507 CAM_0x1fb: 32 CAMERA
 SG_ CHECKSUM : 0|16@1+ (1,0) [0|65535] "" XXX
 SG_ COUNTER : 16|8@1+ (1,0) [0|255] "" XXX

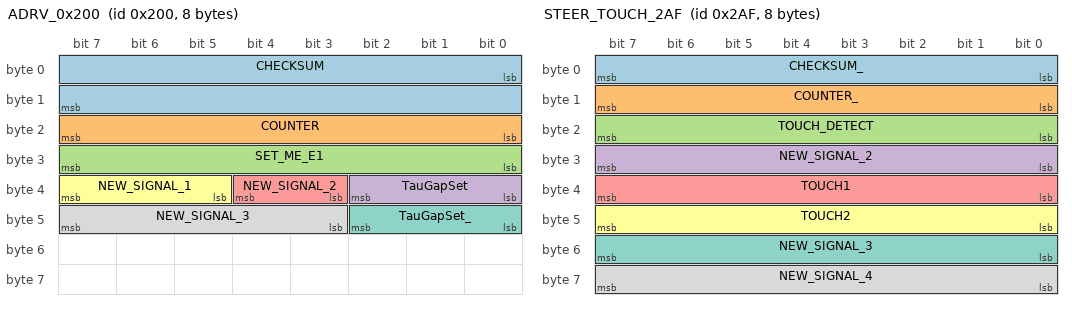
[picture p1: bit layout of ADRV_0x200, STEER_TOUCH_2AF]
BO_ 512 ADRV_0x200: 8 ADRV
 SG_ CHECKSUM : 0|16@1+ (1,0) [0|65535] "" XXX
 SG_ COUNTER : 16|8@1+ (1,0) [0|255] "" XXX
 SG_ SET_ME_E1 : 24|8@1+ (1,0) [0|255] "" XXX
 SG_ TauGapSet : 32|3@1+ (1,0) [0|7] "" XXX
 SG_ NEW_SIGNAL_2 : 35|2@1+ (1,0) [0|3] "" XXX
 SG_ NEW_SIGNAL_1 : 39|3@0+ (1,0) [0|7] "" XXX
 SG_ TauGapSet_ : 42|3@0+ (1,0) [0|31] "" XXX
 SG_ NEW_SIGNAL_3 : 47|5@0+ (1,0) [0|31] "" XXX

BO_ 513 RADAR_0x201: 32 FRONT_RADAR
 SG_ CHECKSUM : 0|16@1+ (1,0) [0|65535] "" XXX
 SG_ COUNTER : 16|8@1+ (1,0) [0|255] "" XXX

BO_ 528 RADAR_0x210: 32 FRONT_RADAR
 SG_ CHECKSUM : 0|16@1+ (1,0) [0|65535] "" XXX
 SG_ COUNTER : 16|8@1+ (1,0) [0|255] "" XXX

BO_ 529 RADAR_0x211: 32 FRONT_RADAR
 SG_ CHECKSUM : 0|16@1+ (1,0) [0|65535] "" XXX
 SG_ COUNTER : 16|8@1+ (1,0) [0|255] "" XXX

BO_ 530 RADAR_0x212: 32 FRONT_RADAR
 SG_ CHECKSUM : 0|16@1+ (1,0) [0|65535] "" XXX
 SG_ COUNTER : 16|8@1+ (1,0) [0|255] "" XXX

BO_ 531 RADAR_0x213: 32 FRONT_RADAR
 SG_ CHECKSUM : 0|16@1+ (1,0) [0|65535] "" XXX
 SG_ COUNTER : 16|8@1+ (1,0) [0|255] "" XXX

BO_ 532 RADAR_0x214: 32 FRONT_RADAR
 SG_ CHECKSUM : 0|16@1+ (1,0) [0|65535] "" XXX
 SG_ COUNTER : 16|8@1+ (1,0) [0|255] "" XXX

BO_ 533 RADAR_0x215: 32 FRONT_RADAR
 SG_ CHECKSUM : 0|16@1+ (1,0) [0|65535] "" XXX
 SG_ COUNTER : 16|8@1+ (1,0) [0|255] "" XXX

BO_ 534 RADAR_0x216: 32 FRONT_RADAR
 SG_ CHECKSUM : 0|16@1+ (1,0) [0|65535] "" XXX
 SG_ COUNTER : 16|8@1+ (1,0) [0|255] "" XXX

BO_ 535 RADAR_0x217: 32 FRONT_RADAR
 SG_ CHECKSUM : 0|16@1+ (1,0) [0|65535] "" XXX
 SG_ COUNTER : 16|8@1+ (1,0) [0|255] "" XXX

BO_ 536 RADAR_0x218: 32 FRONT_RADAR
 SG_ CHECKSUM : 0|16@1+ (1,0) [0|65535] "" XXX
 SG_ COUNTER : 16|8@1+ (1,0) [0|255] "" XXX

BO_ 537 RADAR_0x219: 32 FRONT_RADAR
 SG_ CHECKSUM : 0|16@1+ (1,0) [0|65535] "" XXX
 SG_ COUNTER : 16|8@1+ (1,0) [0|255] "" XXX

BO_ 538 RADAR_0x21a: 32 FRONT_RADAR
 SG_ CHECKSUM : 0|16@1+ (1,0) [0|65535] "" XXX
 SG_ COUNTER : 16|8@1+ (1,0) [0|255] "" XXX

BO_ 539 RADAR_0x21b: 32 FRONT_RADAR
 SG_ CHECKSUM : 0|16@1+ (1,0) [0|65535] "" XXX
 SG_ COUNTER : 16|8@1+ (1,0) [0|255] "" XXX

BO_ 540 RADAR_0x21c: 32 FRONT_RADAR
 SG_ CHECKSUM : 0|16@1+ (1,0) [0|65535] "" XXX
 SG_ COUNTER : 16|8@1+ (1,0) [0|255] "" XXX

BO_ 541 RADAR_0x21d: 32 FRONT_RADAR
 SG_ CHECKSUM : 0|16@1+ (1,0) [0|65535] "" XXX
 SG_ COUNTER : 16|8@1+ (1,0) [0|255] "" XXX

BO_ 542 RADAR_0x21e: 32 FRONT_RADAR
 SG_ CHECKSUM : 0|16@1+ (1,0) [0|65535] "" XXX
 SG_ COUNTER : 16|8@1+ (1,0) [0|255] "" XXX

BO_ 543 RADAR_0x21f: 32 FRONT_RADAR
 SG_ CHECKSUM : 0|16@1+ (1,0) [0|65535] "" XXX
 SG_ COUNTER : 16|8@1+ (1,0) [0|255] "" XXX

BO_ 560 HCU_STATUS_230: 32 XXX
 SG_ CHECKSUM : 0|16@1+ (1,0) [0|65535] "" XXX
 SG_ COUNTER : 16|8@1+ (1,0) [0|255] "" XXX
 SG_ HYBRID_POWER_FLOW_MODE : 170|4@1+ (1,0) [0|15] "" XXX

CM_ BO_ 560 "Hyundai/Kia CAN-FD hybrid power-flow status observed on ECAN at 10 Hz; ACAN 0x230/DLC16 is an unrelated radar frame.";
CM_ SG_ 560 HYBRID_POWER_FLOW_MODE "Reverse-engineered enum; observed values 1, 2, and 6 correspond to the OEM EV indicator being on.";

BO_ 576 RADAR_0x240: 16 FRONT_RADAR
 SG_ CHECKSUM : 0|16@1+ (1,0) [0|65535] "" XXX
 SG_ COUNTER : 16|8@1+ (1,0) [0|255] "" XXX

BO_ 593 RADAR_0x251: 16 FRONT_RADAR
 SG_ CHECKSUM : 0|16@1+ (1,0) [0|65535] "" XXX
 SG_ COUNTER : 16|8@1+ (1,0) [0|255] "" XXX

BO_ 674 CAM_0x2a2: 32 CAMERA
 SG_ CHECKSUM : 0|16@1+ (1,0) [0|65535] "" XXX
 SG_ COUNTER : 16|8@1+ (1,0) [0|255] "" XXX

BO_ 675 CAM_0x2a3: 32 CAMERA
 SG_ CHECKSUM : 0|16@1+ (1,0) [0|65535] "" XXX
 SG_ COUNTER : 16|8@1+ (1,0) [0|255] "" XXX

BO_ 676 CAM_0x2a4: 24 XXX
 SG_ CHECKSUM : 0|16@1+ (1,0) [0|65535] "" XXX
 SG_ COUNTER : 16|8@1+ (1,0) [0|255] "" XXX
 SG_ LEFT_LANE_PROB : 31|8@0+ (1,0) [0|255] "" XXX
 SG_ RIGHT_LANE_PROB : 39|8@0+ (1,0) [0|255] "" XXX
 SG_ LEFT_LANE_TYPE : 43|4@0+ (1,0) [0|15] "" XXX
 SG_ RIGHT_LANE_TYPE : 47|4@0+ (1,0) [0|15] "" XXX
 SG_ LEFT_LANE_COLOR : 48|4@1+ (1,0) [0|15] "" XXX
 SG_ RIGHT_LANE_COLOR : 52|4@1+ (1,0) [0|15] "" XXX
 SG_ LEFT_LANE_LINE : 56|2@1+ (1,0) [0|3] "" XXX
 SG_ SET_ME_0 : 58|2@1+ (1,0) [0|3] "" XXX
 SG_ RIGHT_LANE_LINE : 60|2@1+ (1,0) [0|3] "" XXX
 SG_ SET_ME_0_2 : 62|2@1+ (1,0) [0|3] "" XXX
 SG_ NEW_SIGNAL_2 : 67|4@0+ (1,0) [0|15] "" XXX
 SG_ NEW_SIGNAL_1 : 71|4@0+ (1,0) [0|15] "" XXX
 SG_ NEW_SIGNAL_4 : 75|4@0+ (1,0) [0|15] "" XXX
 SG_ NEW_SIGNAL_3 : 79|4@0+ (1,0) [0|15] "" XXX
 SG_ NEW_SIGNAL_5 : 80|10@1- (1,0) [0|1023] "" XXX
 SG_ NEW_SIGNAL_6 : 96|10@1- (1,0) [0|1023] "" XXX
 SG_ NEW_SIGNAL_7 : 112|16@1+ (1,0) [0|65535] "" XXX
 SG_ NEW_SIGNAL_8 : 128|16@1+ (1,0) [0|65535] "" XXX
 SG_ NEW_SIGNAL_9 : 144|16@1+ (1,0) [0|65535] "" XXX
 SG_ NEW_SIGNAL_10 : 160|16@1+ (1,0) [0|65535] "" XXX
 SG_ NEW_SIGNAL_11 : 176|16@1+ (1,0) [0|65535] "" XXX
 SG_ NEW_SIGNAL_12 : 192|16@1+ (1,0) [0|65535] "" XXX
 SG_ NEW_SIGNAL_13 : 208|16@1+ (1,0) [0|65535] "" XXX
 SG_ NEW_SIGNAL_14 : 224|16@1+ (1,0) [0|65535] "" XXX
 SG_ NEW_SIGNAL_15 : 240|16@1+ (1,0) [0|65535] "" XXX

BO_ 687 STEER_TOUCH_2AF: 8 XXX
 SG_ CHECKSUM_ : 7|8@0+ (1,0) [0|255] "" XXX
 SG_ COUNTER_ : 8|8@1+ (1,0) [0|255] "" XXX
 SG_ TOUCH_DETECT : 23|8@0+ (1,0) [0|255] "" XXX
 SG_ NEW_SIGNAL_2 : 31|8@0+ (1,0) [0|255] "" XXX
 SG_ TOUCH1 : 39|8@0+ (1,0) [0|255] "" XXX
 SG_ TOUCH2 : 47|8@0+ (1,0) [0|255] "" XXX
 SG_ NEW_SIGNAL_3 : 55|8@0+ (1,0) [0|255] "" XXX
 SG_ NEW_SIGNAL_4 : 63|8@0+ (1,0) [0|255] "" XXX

BO_ 699 CAM_0x2bb: 32 CAMERA
 SG_ CHECKSUM : 0|16@1+ (1,0) [0|65535] "" XXX
 SG_ COUNTER : 16|8@1+ (1,0) [0|255] "" XXX

BO_ 700 CAM_0x2bc: 32 CAMERA
 SG_ CHECKSUM : 0|16@1+ (1,0) [0|65535] "" XXX
 SG_ COUNTER : 16|8@1+ (1,0) [0|255] "" XXX

BO_ 701 CAM_0x2bd: 32 CAMERA
 SG_ CHECKSUM : 0|16@1+ (1,0) [0|65535] "" XXX
 SG_ COUNTER : 16|8@1+ (1,0) [0|255] "" XXX

BO_ 702 CAM_0x2be: 32 CAMERA
 SG_ CHECKSUM : 0|16@1+ (1,0) [0|65535] "" XXX
 SG_ COUNTER : 16|8@1+ (1,0) [0|255] "" XXX

BO_ 736 MANUAL_SPEED_LIMIT_ASSIST: 32 XXX
 SG_ CHECKSUM : 0|16@1+ (1,0) [0|65535] "" XXX
 SG_ COUNTER : 16|8@1+ (1,0) [0|255] "" XXX
 SG_ MSLA_STATUS : 26|2@1+ (1,0) [0|3] "" XXX
 SG_ MSLA_ENABLED : 38|1@1+ (1,0) [0|1] "" XXX
 SG_ MAX_SPEED : 55|8@0+ (1,0) [0|255] "" XXX
 SG_ MAX_SPEED_COPY : 144|8@1+ (1,0) [0|255] "" XXX

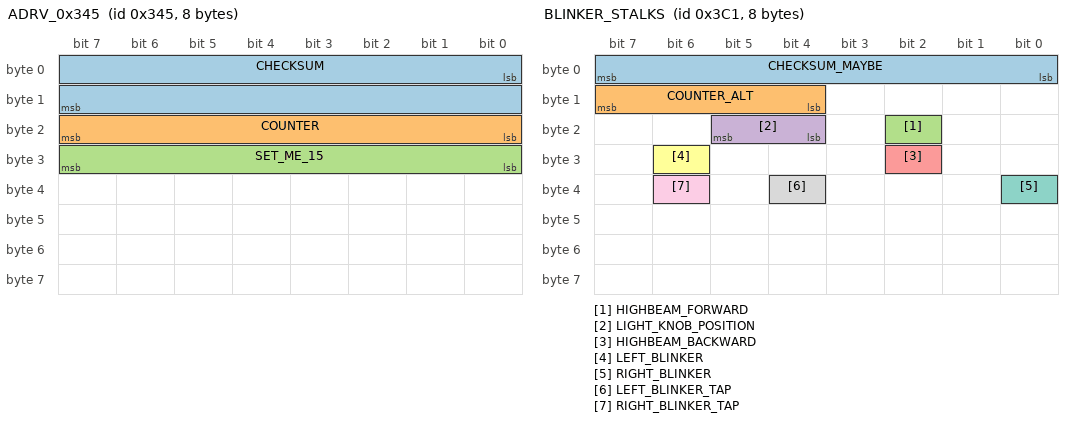
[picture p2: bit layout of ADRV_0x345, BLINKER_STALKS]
BO_ 837 ADRV_0x345: 8 ADRV
 SG_ CHECKSUM : 0|16@1+ (1,0) [0|65535] "" XXX
 SG_ COUNTER : 16|8@1+ (1,0) [0|255] "" XXX
 SG_ SET_ME_15 : 24|8@1+ (1,0) [0|255] "" XXX

BO_ 866 CAM_0x362: 32 CAMERA
 SG_ CHECKSUM : 0|16@1+ (1,0) [0|65535] "" XXX
 SG_ COUNTER : 16|8@1+ (1,0) [0|255] "" XXX
 SG_ LEFT_LANE_PROB : 31|8@0+ (1,0) [0|255] "" XXX
 SG_ RIGHT_LANE_PROB : 39|8@0+ (1,0) [0|255] "" XXX
 SG_ LEFT_LANE_TYPE : 43|4@0+ (1,0) [0|15] "" XXX
 SG_ RIGHT_LANE_TYPE : 47|4@0+ (1,0) [0|15] "" XXX
 SG_ LEFT_LANE_COLOR : 48|4@1+ (1,0) [0|15] "" XXX
 SG_ RIGHT_LANE_COLOR : 52|4@1+ (1,0) [0|15] "" XXX
 SG_ LEFT_LANE_LINE : 56|2@1+ (1,0) [0|3] "" XXX
 SG_ SET_ME_0 : 58|2@1+ (1,0) [0|3] "" XXX
 SG_ RIGHT_LANE_LINE : 60|2@1+ (1,0) [0|3] "" XXX
 SG_ SET_ME_0_2 : 62|2@1+ (1,0) [0|3] "" XXX
 SG_ NEW_SIGNAL_2 : 67|4@0+ (1,0) [0|15] "" XXX
 SG_ NEW_SIGNAL_1 : 71|4@0+ (1,0) [0|15] "" XXX
 SG_ NEW_SIGNAL_4 : 75|4@0+ (1,0) [0|15] "" XXX
 SG_ NEW_SIGNAL_3 : 79|4@0+ (1,0) [0|15] "" XXX
 SG_ NEW_SIGNAL_5 : 80|10@1- (1,0) [0|1023] "" XXX
 SG_ NEW_SIGNAL_6 : 96|10@1- (1,0) [0|1023] "" XXX
 SG_ NEW_SIGNAL_7 : 112|16@1+ (1,0) [0|65535] "" XXX
 SG_ NEW_SIGNAL_8 : 128|16@1+ (1,0) [0|65535] "" XXX
 SG_ NEW_SIGNAL_9 : 144|16@1+ (1,0) [0|65535] "" XXX
 SG_ NEW_SIGNAL_10 : 160|16@1+ (1,0) [0|65535] "" XXX
 SG_ NEW_SIGNAL_11 : 176|16@1+ (1,0) [0|65535] "" XXX
 SG_ NEW_SIGNAL_12 : 192|16@1+ (1,0) [0|65535] "" XXX
 SG_ NEW_SIGNAL_13 : 208|16@1+ (1,0) [0|65535] "" XXX
 SG_ NEW_SIGNAL_14 : 224|16@1+ (1,0) [0|65535] "" XXX
 SG_ NEW_SIGNAL_15 : 240|16@1+ (1,0) [0|65535] "" XXX

BO_ 868 CANFD_HDA_INFO_364: 16 XXX
 SG_ LinkClass : 64|3@1+ (1,0) [0|7] "" XXX
 SG_ Frwinfo : 67|3@1+ (1,0) [0|7] "" XXX
 SG_ SpeedUnit : 70|2@1+ (1,0) [0|3] "" XXX
 SG_ SPEED_LIMIT : 79|8@0+ (1,0) [0|255] "km/h" XXX
 SG_ CountryCode : 80|10@1+ (1,0) [0|1023] "" XXX
 SG_ MapSource : 91|3@1+ (1,0) [0|7] "" XXX
 SG_ TollExist : 94|2@1+ (1,0) [0|3] "" XXX
 SG_ TunnelExist : 102|2@1+ (1,0) [0|3] "" XXX

BO_ 874 BLINDSPOTS_FRONT_CORNER_2: 16 XXX
 SG_ CHECKSUM : 0|16@1+ (1,0) [0|65535] "" XXX
 SG_ COUNTER : 16|8@1+ (1,0) [0|255] "" XXX
 SG_ RIGHT_BSD : 27|1@0+ (1,0) [0|1] "" XXX
 SG_ LEFT_BSD : 28|1@0+ (1,0) [0|1] "" XXX

BO_ 896 CANFD_NAVI_STATUS_380: 24 XXX
 SG_ CAMERA_STATUS : 24|8@1+ (1,0) [0|255] "" XXX
 SG_ SECTION_ALERT : 84|1@1+ (1,0) [0|1] "" XXX
 SG_ SPEED_LIMIT : 96|8@1+ (1,0) [0|255] "km/h" XXX

BO_ 928 TPMS: 16 XXX
 SG_ PRESSURE_FL : 39|8@0+ (1,0) [0|255] "" XXX
 SG_ PRESSURE_FR : 47|8@0+ (1,0) [0|255] "" XXX
 SG_ PRESSURE_RL : 55|8@0+ (1,0) [0|255] "" XXX
 SG_ PRESSURE_RR : 63|8@0+ (1,0) [0|255] "" XXX
 SG_ STATUS_TPMS : 66|3@0+ (1,0) [0|3] "" XXX
 SG_ UNIT : 68|2@0+ (1,0) [0|3] "" XXX

BO_ 961 BLINKER_STALKS: 8 XXX
 SG_ CHECKSUM_MAYBE : 7|8@0+ (1,0) [0|255] "" XXX
 SG_ COUNTER_ALT : 15|4@0+ (1,0) [0|15] "" XXX
 SG_ HIGHBEAM_FORWARD : 18|1@0+ (1,0) [0|1] "" XXX
 SG_ LIGHT_KNOB_POSITION : 21|2@0+ (1,0) [0|3] "" XXX
 SG_ HIGHBEAM_BACKWARD : 26|1@0+ (1,0) [0|1] "" XXX
 SG_ LEFT_BLINKER : 30|1@0+ (1,0) [0|1] "" XXX
 SG_ RIGHT_BLINKER : 32|1@0+ (1,0) [0|1] "" XXX
 SG_ LEFT_BLINKER_TAP : 36|1@0+ (1,0) [0|1] "" XXX
 SG_ RIGHT_BLINKER_TAP : 38|1@0+ (1,0) [0|1] "" XXX

BO_ 995 BLINKERS_ALT: 16 XXX
 SG_ LEFT_BLINKER : 74|1@0+ (1,0) [0|1] "" XXX
 SG_ RIGHT_BLINKER : 76|1@0+ (1,0) [0|1] "" XXX
 SG_ LEFT_LAMP_ALT : 89|1@0+ (1,0) [0|1] "" XXX
 SG_ LEFT_LAMP : 90|1@0+ (1,0) [0|1] "" XXX
 SG_ RIGHT_LAMP_ALT : 91|1@0+ (1,0) [0|1] "" XXX
 SG_ RIGHT_LAMP : 92|1@0+ (1,0) [0|1] "" XXX
 SG_ NEW_SIGNAL_2 : 95|1@0+ (1,0) [0|1] "" XXX
 SG_ BLINKER_ACTIVE : 97|1@0+ (1,0) [0|1] "" XXX

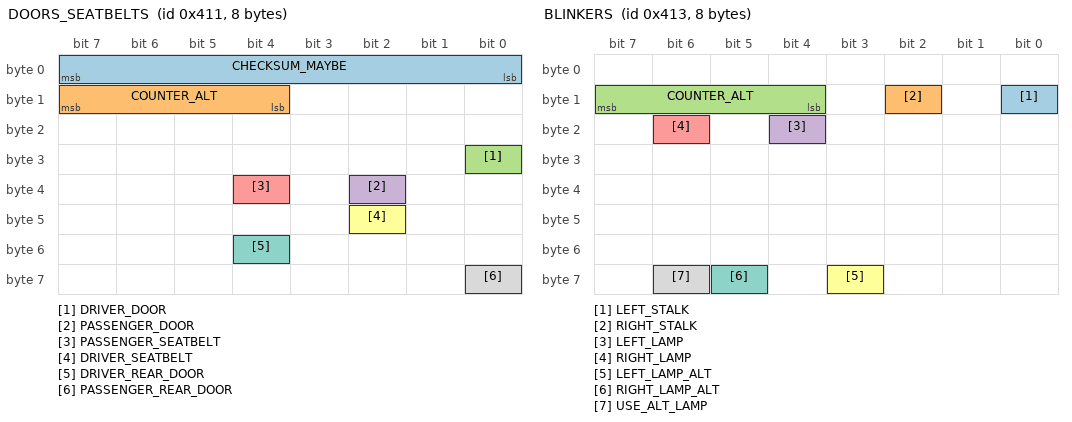
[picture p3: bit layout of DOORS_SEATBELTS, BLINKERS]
BO_ 1041 DOORS_SEATBELTS: 8 XXX
 SG_ CHECKSUM_MAYBE : 7|8@0+ (1,0) [0|65535] "" XXX
 SG_ COUNTER_ALT : 15|4@0+ (1,0) [0|15] "" XXX
 SG_ DRIVER_DOOR : 24|1@1+ (1,0) [0|1] "" XXX
 SG_ PASSENGER_DOOR : 34|1@0+ (1,0) [0|1] "" XXX
 SG_ PASSENGER_SEATBELT : 36|1@0+ (1,0) [0|1] "" XXX
 SG_ DRIVER_SEATBELT : 42|1@0+ (1,0) [0|1] "" XXX
 SG_ DRIVER_REAR_DOOR : 52|1@0+ (1,0) [0|1] "" XXX
 SG_ PASSENGER_REAR_DOOR : 56|1@0+ (1,0) [0|1] "" XXX

BO_ 1043 BLINKERS: 8 XXX
 SG_ LEFT_STALK : 8|1@0+ (1,0) [0|1] "" XXX
 SG_ RIGHT_STALK : 10|1@0+ (1,0) [0|1] "" XXX
 SG_ COUNTER_ALT : 15|4@0+ (1,0) [0|15] "" XXX
 SG_ LEFT_LAMP : 20|1@0+ (1,0) [0|1] "" XXX
 SG_ RIGHT_LAMP : 22|1@0+ (1,0) [0|1] "" XXX
 SG_ LEFT_LAMP_ALT : 59|1@0+ (1,0) [0|1] "" XXX
 SG_ RIGHT_LAMP_ALT : 61|1@0+ (1,0) [0|1] "" XXX
 SG_ USE_ALT_LAMP : 62|1@0+ (1,0) [0|1] "" XXX

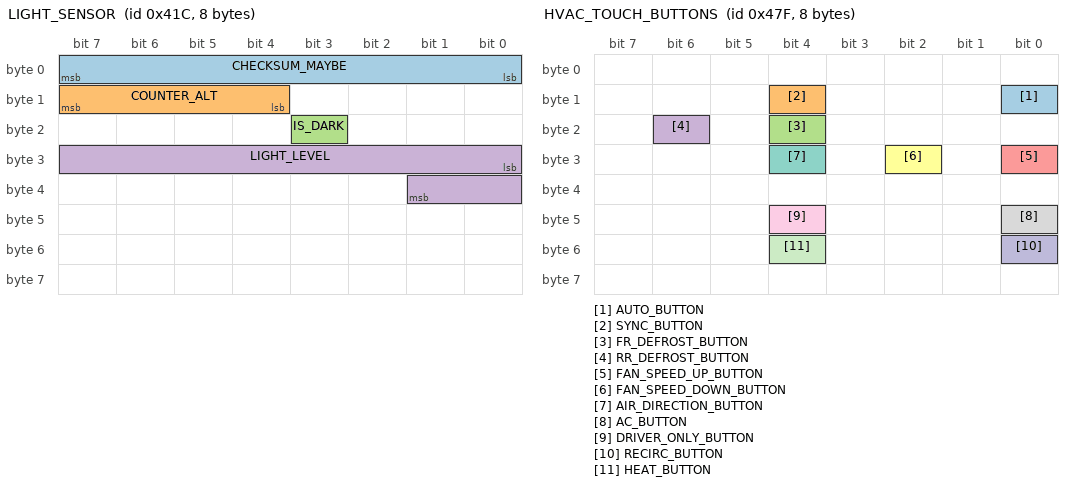
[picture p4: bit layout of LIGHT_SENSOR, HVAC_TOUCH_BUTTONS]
BO_ 1052 LIGHT_SENSOR: 8 XXX
 SG_ CHECKSUM_MAYBE : 7|8@0+ (1,0) [0|255] "" XXX
 SG_ COUNTER_ALT : 15|4@0+ (1,0) [0|15] "" XXX
 SG_ IS_DARK : 19|1@0+ (1,0) [0|1] "" XXX
 SG_ LIGHT_LEVEL : 24|10@1+ (1,0) [0|1023] "" XXX

BO_ 1144 DRIVE_MODE: 8 XXX
 SG_ DRIVE_MODE : 0|16@1+ (1,-61611) [0|61611] "" XXX
 SG_ DRIVE_MODE2 : 28|3@1+ (1,0) [1|3] "" XXX

BO_ 1151 HVAC_TOUCH_BUTTONS: 8 XXX
 SG_ AUTO_BUTTON : 8|1@0+ (1,0) [0|1] "" XXX
 SG_ SYNC_BUTTON : 12|1@0+ (1,0) [0|1] "" XXX
 SG_ FR_DEFROST_BUTTON : 20|1@0+ (1,0) [0|1] "" XXX
 SG_ RR_DEFROST_BUTTON : 22|1@0+ (1,0) [0|1] "" XXX
 SG_ FAN_SPEED_UP_BUTTON : 24|1@0+ (1,0) [0|1] "" XXX
 SG_ FAN_SPEED_DOWN_BUTTON : 26|1@0+ (1,0) [0|1] "" XXX
 SG_ AIR_DIRECTION_BUTTON : 28|1@0+ (1,0) [0|1] "" XXX
 SG_ AC_BUTTON : 40|1@0+ (1,0) [0|1] "" XXX
 SG_ DRIVER_ONLY_BUTTON : 44|1@0+ (1,0) [0|1] "" XXX
 SG_ RECIRC_BUTTON : 48|1@0+ (1,0) [0|1] "" XXX
 SG_ HEAT_BUTTON : 52|1@0+ (1,0) [0|1] "" XXX

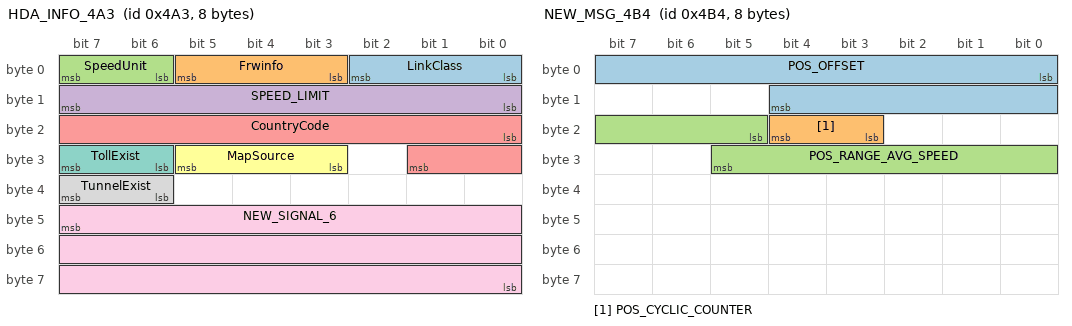
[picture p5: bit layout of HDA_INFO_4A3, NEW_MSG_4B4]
BO_ 1187 HDA_INFO_4A3: 8 XXX
 SG_ LinkClass : 0|3@1+ (1,0) [0|7] "" XXX
 SG_ Frwinfo : 3|3@1+ (1,0) [0|7] "" XXX
 SG_ SpeedUnit : 6|2@1+ (1,0) [0|3] "" XXX
 SG_ SPEED_LIMIT : 15|8@0+ (1,0) [0|255] "" XXX
 SG_ CountryCode : 16|10@1+ (1,0) [0|1023] "" XXX
 SG_ MapSource : 27|3@1+ (1,0) [0|7] "" XXX
 SG_ TollExist : 30|2@1+ (1,0) [0|3] "" XXX
 SG_ TunnelExist : 38|2@1+ (1,0) [0|3] "" XXX
 SG_ NEW_SIGNAL_6 : 47|24@0+ (1,0) [0|16777215] "" XXX

BO_ 1204 NEW_MSG_4B4: 8 XXX
 SG_ POS_OFFSET : 0|13@1+ (1,0) [0|8191] "m" XXX
 SG_ POS_CYCLIC_COUNTER : 19|2@1+ (1,0) [0|3] "" XXX
 SG_ POS_RANGE_AVG_SPEED : 21|9@1+ (1,0) [0|511] "km/h" XXX

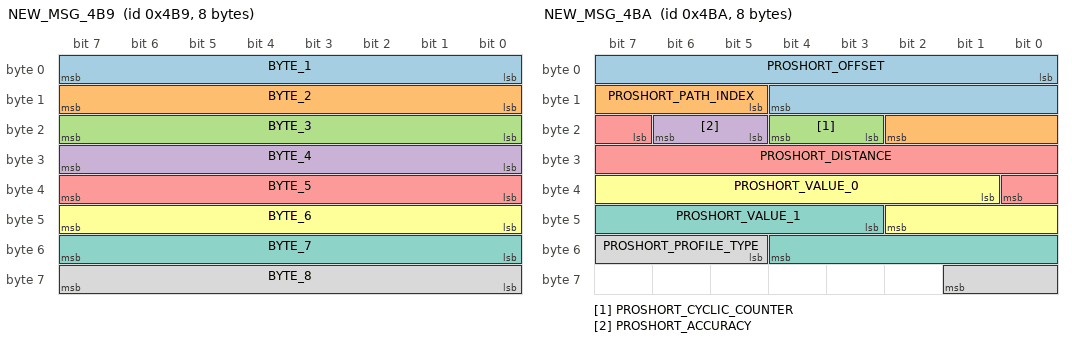
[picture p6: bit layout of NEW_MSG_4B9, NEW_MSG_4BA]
BO_ 1209 NEW_MSG_4B9: 8 XXX
 SG_ BYTE_1 : 7|8@0+ (1,0) [0|255] "" XXX
 SG_ BYTE_2 : 15|8@0+ (1,0) [0|255] "" XXX
 SG_ BYTE_3 : 23|8@0+ (1,0) [0|255] "" XXX
 SG_ BYTE_4 : 31|8@0+ (1,0) [0|255] "" XXX
 SG_ BYTE_5 : 39|8@0+ (1,0) [0|255] "" XXX
 SG_ BYTE_6 : 47|8@0+ (1,0) [0|255] "" XXX
 SG_ BYTE_7 : 55|8@0+ (1,0) [0|255] "" XXX
 SG_ BYTE_8 : 63|8@0+ (1,0) [0|255] "" XXX

BO_ 1210 NEW_MSG_4BA: 8 XXX
 SG_ PROSHORT_OFFSET : 0|13@1+ (1,0) [0|8191] "m" XXX
 SG_ PROSHORT_PATH_INDEX : 13|6@1+ (1,0) [0|63] "" XXX
 SG_ PROSHORT_CYCLIC_COUNTER : 19|2@1+ (1,0) [0|3] "" XXX
 SG_ PROSHORT_ACCURACY : 21|2@1+ (1,0) [0|3] "" XXX
 SG_ PROSHORT_DISTANCE : 23|10@1+ (1,0) [0|1023] "m" XXX
 SG_ PROSHORT_VALUE_0 : 33|10@1+ (1,0) [0|1023] "" XXX
 SG_ PROSHORT_VALUE_1 : 43|10@1+ (1,0) [0|1023] "" XXX
 SG_ PROSHORT_PROFILE_TYPE : 53|5@1+ (1,0) [0|31] "" XXX

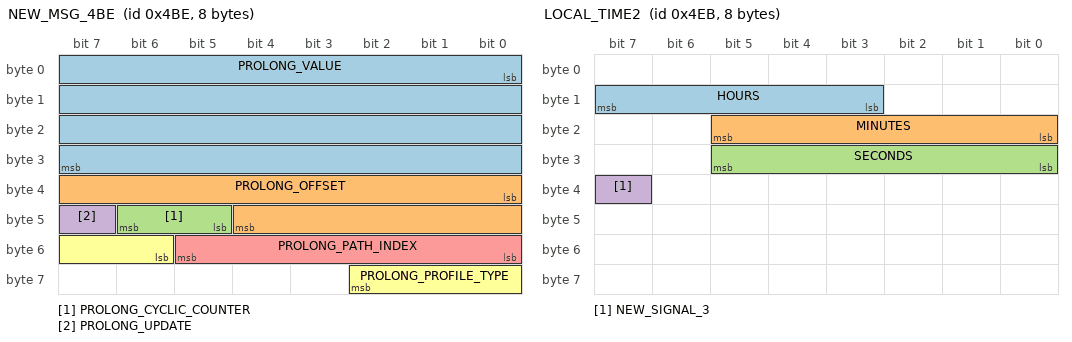
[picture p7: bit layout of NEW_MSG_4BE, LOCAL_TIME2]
BO_ 1214 NEW_MSG_4BE: 8 XXX
 SG_ PROLONG_VALUE : 0|32@1+ (1,0) [0|4294967295] "" XXX
 SG_ PROLONG_OFFSET : 32|13@1+ (1,0) [0|8191] "m" XXX
 SG_ PROLONG_CYCLIC_COUNTER : 45|2@1+ (1,0) [0|3] "" XXX
 SG_ PROLONG_UPDATE : 47|1@1+ (1,0) [0|1] "" XXX
 SG_ PROLONG_PATH_INDEX : 48|6@1+ (1,0) [0|63] "" XXX
 SG_ PROLONG_PROFILE_TYPE : 54|5@1+ (1,0) [0|31] "" XXX

BO_ 1240 CLUSTER_INFO: 8 XXX
 SG_ DISTANCE_UNIT : 0|1@1+ (1,0) [0|1] "" XXX

BO_ 1259 LOCAL_TIME2: 8 XXX
 SG_ HOURS : 15|5@0+ (1,0) [0|31] "" XXX
 SG_ MINUTES : 21|6@0+ (1,0) [0|63] "" XXX
 SG_ SECONDS : 24|6@1+ (1,0) [0|63] "" XXX
 SG_ NEW_SIGNAL_3 : 39|1@0+ (1,0) [0|1] "" XXX

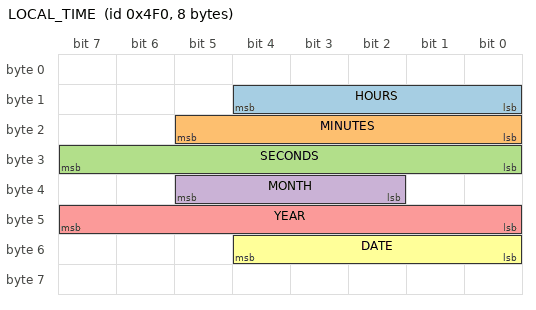
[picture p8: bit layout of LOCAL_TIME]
BO_ 1264 LOCAL_TIME: 8 XXX
 SG_ HOURS : 12|5@0+ (1,0) [0|31] "" XXX
 SG_ MINUTES : 21|6@0+ (1,0) [0|63] "" XXX
 SG_ SECONDS : 31|8@0+ (1,0) [0|59] "" XXX
 SG_ MONTH : 37|4@0+ (1,0) [0|15] "" XXX
 SG_ YEAR : 47|8@0+ (1,0) [0|255] "" XXX
 SG_ DATE : 48|5@1+ (1,0) [0|31] "" XXX

CM_ SG_ 80 HAS_LANE_SAFETY "If 0, hides LKAS 'Lane Safety' menu from vehicle settings";
CM_ SG_ 96 BRAKE_PRESSURE "User applied brake pedal pressure. Ramps from computer applied pressure on falling edge of cruise. Cruise cancels if !=0";
CM_ SG_ 96 AVH_Sta "AVH status. Indicates whether the vehicle is held with the hydraulic service brake";
CM_ SG_ 96 AVH_I_LAMP "AutoHold indicator lamp state. 0 on, 1 off";
CM_ SG_ 96 AVH_LAMP "AutoHold mode and lamp state. 0 off, 1 failure, 2 active, 3 ready";
CM_ SG_ 101 BRAKE_POSITION "User applied brake pedal position, max is ~700. Signed on some vehicles";
CM_ SG_ 272 LKAS_ANGLE_CMD "tracks MDPS->STEERING_ANGLE when not engaged, not STEERING_SENSORS->STEERING_ANGLE";
CM_ SG_ 352 SET_ME_9 "has something to do with AEB settings";
CM_ SG_ 373 ACCEnable "Likely a copy of CAN's TCS13->ACCEnable";
CM_ SG_ 373 DriverBraking "Likely derived from BRAKE->BRAKE_POSITION";
CM_ SG_ 373 DriverBrakingLowSens "Higher threshold version of DriverBraking";
CM_ SG_ 373 PROBABLY_EQUIP "aeb equip?";
CM_ SG_ 416 VSetDis "set speed in display units";
CM_ SG_ 676 LEFT_LANE_LINE "Left lane line confidence";
CM_ SG_ 676 RIGHT_LANE_LINE "Right lane line confidence";
CM_ SG_ 736 MAX_SPEED "Display units. Restricts car from driving above this speed unless accelerator pedal is depressed beyond pressure point";
CM_ SG_ 866 LEFT_LANE_LINE "Left lane line confidence";
CM_ SG_ 866 RIGHT_LANE_LINE "Right lane line confidence";
CM_ SG_ 961 COUNTER_ALT "only increments on change";
CM_ SG_ 1041 COUNTER_ALT "only increments on change";
CM_ SG_ 1043 COUNTER_ALT "only increments on change";
CM_ SG_ 1043 USE_ALT_LAMP "likely 1 on cars that use alt lamp signals";
VAL_ 53 GEAR 0 "P" 5 "D" 6 "N" 7 "R";
VAL_ 64 GEAR 0 "P" 5 "D" 6 "N" 7 "R" 4 "T";
VAL_ 69 GEAR 0 "P" 5 "D" 6 "N" 7 "R";
VAL_ 80 LKA_MODE 1 "warning only" 2 "assist" 6 "off";
VAL_ 80 LKA_ICON 0 "hidden" 1 "grey" 2 "green" 3 "flashing green";
VAL_ 96 TRACTION_AND_STABILITY_CONTROL 0 "On" 5 "Limited" 1 "Off";
VAL_ 96 AVH_Sta 0 "No apply" 1 "Vehicle is held by the service brake" 2 "Being released" 3 "Error Indicator";
VAL_ 96 AVH_I_LAMP 0 "Lamp on" 1 "Lamp off" 2 "Reserved" 3 "Reserved";
VAL_ 96 AVH_LAMP 0 "AVH off" 1 "AVH failure" 2 "AVH active" 3 "AVH ready" 4 "Reserved" 5 "Reserved" 6 "Reserved" 7 "Reserved";
VAL_ 112 GEAR 0 "P" 5 "D" 6 "N" 7 "R";
VAL_ 234 LKA_FAULT 0 "ok" 1 "lka fault";
VAL_ 267 CRUISE_BUTTONS 8 "CRUISE_MAIN" 4 "CANCEL" 1 "RES" 2 "SET" 3 "GAP";
VAL_ 272 LKA_MODE 1 "warning only" 2 "assist" 6 "off";
VAL_ 272 LKA_ICON 0 "hidden" 1 "grey" 2 "green" 3 "flashing green";
VAL_ 272 LKAS_ANGLE_ACTIVE 1 "not active" 2 "active";
VAL_ 298 LKA_MODE 1 "warning only" 2 "assist" 6 "off";
VAL_ 298 LKA_ICON 0 "hidden" 1 "grey" 2 "green" 3 "flashing green";
VAL_ 304 PARK_BUTTON 1 "Pressed" 2 "Not Pressed";
VAL_ 304 KNOB_POSITION 1 "R" 2 "N (on R side)" 3 "Centered" 4 "N (on D side)" 5 "D";
VAL_ 304 GEAR 1 "P" 2 "R" 3 "N" 4 "D";
VAL_ 352 AEB_SETTING 1 "off" 2 "warning only" 3 "active assist";
VAL_ 353 FCA_ICON 0 "HIDDEN" 1 "ORANGE" 2 "RED";
VAL_ 353 FCA_ALT_ICON 0 "HIDDEN" 1 "ORANGE" 3 "RED";
VAL_ 353 LKA_ICON 0 "HIDDEN" 1 "ORANGE" 3 "GRAY" 4 "GREEN";
VAL_ 353 HBA_ICON 0 "HIDDEN" 1 "GRAY" 2 "GREEN";
VAL_ 353 FCA_IMAGE 0 "HIDDEN" 2 "VISIBLE";
VAL_ 353 BCA_LEFT 0 "HIDDEN" 1 "VISIBLE" 2 "VISIBLE+ICON";
VAL_ 353 BCA_RIGHT 0 "HIDDEN" 1 "VISIBLE" 2 "VISIBLE+ICON";
VAL_ 353 LCA_LEFT_ARROW 0 "HIDDEN" 1 "VISIBLE";
VAL_ 353 LCA_RIGHT_ARROW 0 "HIDDEN" 1 "VISIBLE";
VAL_ 353 CENTERLINE 0 "HIDDEN" 1 "GREEN";
VAL_ 353 TARGET 0 "HIDDEN" 1 "BLUE" 3 "WHITE";
VAL_ 353 LANELINE_LEFT 0 "GRAY" 1 "HIDDEN" 2 "WHITE" 4 "ORANGE" 6 "GREEN";
VAL_ 353 LANELINE_RIGHT 0 "GRAY" 1 "HIDDEN" 2 "WHITE" 4 "ORANGE" 6 "GREEN";
VAL_ 353 LANE_HIGHLIGHT 0 "HIDDEN" 1 "GREEN" 2 "WHITE" 3 "BLUE" 4 "ORANGE" 5 "RED";
VAL_ 353 LANE_LEFT 0 "HIDDEN" 1 "GREEN";
VAL_ 353 LANE_RIGHT 0 "HIDDEN" 1 "GREEN";
VAL_ 353 LANE_ZOOM 0 "ZOOM" 1 "HIDDEN";
VAL_ 353 ALERTS_1 0 "HIDDEN" 1 "WARNING_ONLY_CAR_CENTER" 2 "WARNING_ONLY_CAR_LEFT" 3 "WARNING_ONLY_CAR_RIGHT" 4 "WARNING_ONLY_LEFT" 5 "WARNING_ONLY_RIGHT" 11 "EMERGENCY_BRAKING_CAR_CENTER" 12 "EMERGENCY_BRAKING_CAR_LEFT" 13 "EMERGENCY_BRAKING_CAR_RIGHT" 14 "EMERGENCY_BRAKING_LEFT" 15 "EMERGENCY_BRAKING_RIGHT" 21 "EMERGENCY_STEERING_CAR_LEFT" 22 "EMERGENCY_STEERING_CAR_RIGHT" 23 "EMERGENCY_STEERING_CAR_LEFT_AWAY" 24 "EMERGENCY_STEERING_CAR_RIGHT_AWAY" 25 "EMERGENCY_STEERING_REAR_LEFT" 26 "EMERGENCY_STEERING_REAR_RIGHT" 33 "DRIVE_CAREFULLY";
VAL_ 353 ALERTS_2 0 "HIDDEN" 1 "KEEP_HANDS_ON_STEERING_WHEEL" 2 "KEEP_HANDS_ON_STEERING_WHEEL_RED" 3 "LANE_FOLLOWING_ASSIST_DEACTIVATED" 4 "HIGHWAY_DRIVING_ASSIST_DEACTIVATED" 5 "CONSIDER_TAKING_A_BREAK" 6 "PRESS_OK_BUTTON_TO_ENABLE_LANE_CHANGE_ASSIST" 7 "COLLISION_RISK_VEHICLE_TAKING_EMERGENCY_CONTROL" 8 "TAKE_CONTROL_OF_THE_VEHICLE_IMMEDIATELY_VEHICLE_IS_STOPPING" 9 "TAKE_CONTROL_OF_THE_VEHICLE_IMMEDIATELY" 11 "HIGHWAY_DRIVING_PILOT_SYSTEM_DEACTIVATED_AUDIBLE" 12 "KEEP_YOUR_EYES_ON_THE_ROAD" 13 "HIGHWAY_DRIVING_PILOT_CONDITIONS_NOT_MET_AUDIBLE" 14 "COLLISION_RISK_VEHICLE_TAKING_EMERGENCY_CONTROL" 15 "SET_THE_WIPER_AND_LIGHT_CONTROLS_TO_AUTO" 16 "BE_PREPARED_TO_TAKE_CONTROL_OF_THE_VEHICLE_AT_ANY_TIME" 21 "TAKE_CONTROL_OF_THE_VEHICLE_IMMEDIATELY_VEHICLE_IS_STOPPING" 10 "TAKE_CONTROL_OF_THE_VEHICLE_IMMEDIATELY";
VAL_ 353 ALERTS_3 0 "HIDDEN" 1 "AUTOMATICALLY_ADJUSTING_TO_THE_POSTED_SPEED_LIMIT" 2 "SET_SPEED_CHANGED" 3 "AUTOMATICALLY_ADJUSTING_TO_THE_POSTED_SPEED_LIMIT" 4 "SET_SPEED_CHANGED" 7 "DISTANCE_1" 8 "DISTANCE_2" 9 "DISTANCE_3" 10 "DISTANCE_4" 17 "DRIVE_CAREFULLY" 18 "CHECK_SURROUNDINGS" 19 "CONDITIONS_NOT_MET" 20 "LANES_NOT_DETECTED" 21 "CURVE_TOO_SHARP" 22 "LANE_TOO_NARROW" 23 "ROAD_TYPE_NOT_SUPPORTED" 24 "UNAVAILABLE_WITH_HAZARD_LIGHTS_ON" 25 "VEHICLE_SPEED_IS_TOO_LOW" 26 "KEEP_HANDS_ON_STEERING_WHEEL" 27 "LANE_TYPE_NOT_SUPPORTED" 28 "LANE_ASSIST_CANCELED_STEERING_INPUT_DETECTED";
VAL_ 353 ALERTS_4 0 "HIDDEN" 1 "TAKE_FOOT_OFF_THE_ACCELERATOR_PEDAL" 2 "TAKE_FOOT_OFF_THE_BRAKE_PEDAL" 3 "UNAVAILABLE_WHILE_HIGHWAY_DRIVING_PILOT_SYSTEM_IS_ACTIVE" 4 "TO_EXIT_HDP_GRASP_THE_STEERING_WHEEL_THEN_PRESS_AND_HOLD_THE_HDP_BUTTON" 5 "ACCELERATOR_PEDAL_OPERATION_LIMITED_FOR_SAFETY" 6 "TURN_OFF_HAZARD_WARNING_LIGHTS_AND_TURN_SIGNAL" 7 "KEEP_THE_DRIVERS_SEAT_IN_A_SAFE_DRIVING_POSITION" 16 "SET_SPEED_CHANGED" 17 "ACTIVATING_WINDSHIELD_DEFOG_TO_MAINTAIN_THE_DRIVERS_VIEW" 18 "SET_THE_WIPER_AND_LIGHT_CONTROLS_TO_AUTO" 19 "VEHICLE_SPEED_REDUCED_FOR_SAFETY_MERGING_LANES_AHEAD" 20 "SPEED_REDUCED_FOR_SAFETY_CONSTRUCTION_ZONE_DETECTED" 21 "VEHICLE_SPEED_LIMITED_SENSOR_DETECTION_RANGE_LIMITED" 22 "PREPARE_TO_TAKE_CONTROL_UNSUPPORTED_ROAD_TYPE_AHEAD" 23 "PREPARE_TO_TAKE_CONTROL_ENTRANCE_AND_EXIT_RAMPS_AHEAD" 24 "PREPARE_TO_TAKE_CONTROL_TOLLGATE_AHEAD" 25 "PREPARE_TO_TAKE_CONTROL_ROAD_EVENT_AHEAD" 26 "CLEARING_PATH_FOR_EMERGENCY_VEHICLE" 27 "VEHICLE_IS_TOO_SLOW_COMPARED_TO_TRAFFIC_FLOW" 28 "AFTER_SUNSET_HDP_IS_AVAILABLE_IN_AN_INSIDE_LANE_BEHIND_A_LEADING_VEHICLE" 29 "VEHICLE_SPEED_LIMITED_MERGING_LANES_AHEAD" 30 "VEHICLE_SPEED_LIMITED_CONSTRUCTION_ZONE_DETECTED" 31 "VEHICLE_SPEED_TEMPORARILY_LIMITED_FOR_SAFETY" 32 "PRESS_AND_HOLD_THE_BUTTON_TO_ACTIVATE_HIGHWAY_DRIVING_PILOT" 40 "HIGHWAY_DRIVING_PILOT_SYSTEM_IS_AVAILABLE" 64 "RESTART_VEHICLE_AFTER_EMERGENCY_STOP" 65 "CONNECTED_SERVICES_UNAVAILABLE" 66 "AVAILABLE_AFTER_VEHICLE_SOFTWARE_IS_UPDATED" 67 "ROAD_TYPE_NOT_SUPPORTED" 68 "ONLY_AVAILABLE_WHILE_DRIVING_ON_HIGHWAY_LANES" 69 "UNAVAILABLE_WHILE_OTHER_WARNINGS_ARE_ACTIVE" 70 "CANNOT_ACTIVATE_AT_ENTRANCE_EXIT_RAMPS" 71 "LANE_UNSUPPORTED" 72 "NOT_AVAILABLE_IN_THIS_COUNTRY" 79 "CHECKING_THE_DETECTION_RANGE_OF_THE_SENSOR" 80 "SHIFT_TO_D" 81 "ENGINE_STOPPED_BY_AUTO_STOP" 82 "INCREASE_DISTANCE_FROM_VEHICLE_AHEAD" 83 "VEHICLE_SPEED_IS_TOO_HIGH" 84 "CENTER_VEHICLE_IN_THE_LANE" 85 "PARKING_ASSIST_IS_ACTIVE" 86 "ESC_ACTIVIATION_REQUIRED" 87 "UNFOLD_SIDE_VIEW_MIRRORS" 88 "UNAVAILABLE_IN_THE_OUTER_LANE_AFTER_SUNSET" 89 "VEHICLE_SPEED_LIMITED_AFTER_SUNSET_FOR_SAFETY" 90 "LEADING_VEHICLE_NOT_DETECTED" 104 "AGGRESSIVE_BRAKING_OR_STEERING_DETECTED" 110 "SENSOR_AUTO_CALIBRATION_IN_PROGRESS_THIS_MAY_TAKE_SEVERAL_MINUTES" 111 "HIGHWAY_DRIVING_PILOT_WILL_BE_AVAILABLE_SHORTLY" 112 "IF_STEERING_WHEEL_IS_USED_HDP_WILL_BE_DEACTIVATED" 120 "IMPACT_DETECTED" 128 "UNSUITABLE_USE_OF_ACCELERATOR_PEDAL_DETECTED" 129 "GEAR_SHIFTER_USE_DETECTED" 130 "UNSUITABLE_BRAKE_PEDAL_USE_DETECTED" 131 "VEHICLE_START_BUTTON_PRESSED" 132 "VEHICLE_HAS_BEEN_STOPPED_FOR_TOO_LONG" 141 "TRAFFIC_CONGESTION_HAS_CLEARED" 142 "ENTRANCE_AND_EXIT_RAMPS_AHEAD" 143 "UNSUPPORTED_LANE_AHEAD" 144 "UNSUPPORTED_ROAD_TYPE_AHEAD" 145 "LANE_DEPARTURE_DETECTED" 146 "MAXIMUM_SPEED_EXCEEDED" 147 "HIGHWAY_DRIVING_PILOT_LIMITED_ABNORMAL_VEHICLE_CONTROLLER_STATUS" 148 "WIPER_LIGHT_CONTROL_SETTINGS_ARE_UNSUITABLE_FOR_USE_WITH_HDP" 149 "WINDSHIELD_DEFOG_SYSTEM_STATUS_IS_UNSUITABLE_FOR_USE_WITH_HDP" 150 "HAZARD_WARNING_LIGHTS_OR_TURN_SIGNAL_OPERATION_DETECTED" 151 "PERFORMING_EVASIVE_STEERING_OBSTACLES_DETECTED_AHEAD" 152 "HIGHWAY_DRIVING_PILOT_LIMITED_SENSOR_DETECTION_RANGE_LIMITED" 160 "CHECK_HIGHWAY_DRIVING_PILOT_SYSTEM" 161 "SAFETY_FUNCTION_ACTIVATED" 176 "CAMERA_OBSCURED" 177 "RADAR_BLOCKED" 178 "LIDAR_BLOCKED" 179 "AIRBAG_WARNING_LIGHT_IS_ON" 180 "ATTACHED_TRAILED_DETECTED" 181 "HIGH_OUTSIDE_TEMPERATURE" 182 "LOW_OUTSIDE_TEMPERATURE" 190 "UNAVAILABLE_DUE_TO_THE_ROAD_EVENT_INFORMATION_RECEIVED" 191 "UNAVAILABLE_NEAR_TOLLGATES" 192 "DRIVERS_SEAT_IS_NOT_IN_A_SAFE_DRIVING_POSITION" 193 "VEHICLE_DRIVING_THE_WRONG_WAY_DETECTED_AHEAD" 194 "EMERGENCY_VEHICLE_DETECTED" 195 "OBSTACLE_DETECTED_AHEAD" 196 "SENSOR_BLOCKED_DUE_TO_RAIN_SNOW_OR_ROAD_DEBRIS" 197 "SLIPPERY_ROAD_SURFACE_DETECTED" 198 "CONSTRUCTION_ZONE_DETECTED_AHEAD" 199 "PEDESTRIAN_DETECTED_AHEAD" 200 "UNSUITABLE_DRIVERS_SEAT_POSITION_DETECTED" 201 "FOLDED_SIDE_VIEW_MIRRORS_DETECTED" 208 "VEHICLE_POSITION_NOT_DETECTED" 209 "LANE_NOT_DETECTED" 210 "DRIVER_NOT_DETECTED" 211 "KEEP_YOUR_EYES_ON_THE_ROAD" 212 "LEADING_VEHICLE_REQUIRED_AFTER_SUNSET" 213 "TBD" 240 "LOW_FUEL" 241 "LOW_TIRE_PRESSURE" 242 "DOOR_OPEN" 243 "TRUNK_OPEN" 244 "HOOD_OPEN" 245 "SEAT_BELT_NOT_FASTENED" 246 "PARKING_BRAKE_ACTIVATED" 247 "LOW_EV_BATTERY" 248 "HDP_DEACTIVATION_DELAYED_RISK_OF_COLLISION_DETECTED" 249 "LIFTGATE_OPENED";
VAL_ 353 ALERTS_5 0 "HIDDEN" 1 "DRIVERS_GRASP_NOT_DETECTED_DRIVING_SPEED_WILL_BE_LIMITED" 2 "WATCH_FOR_SURROUNDING_VEHICLES" 3 "SMART_CRUISE_CONTROL_DEACTIVATED" 4 "SMART_CRUISE_CONTROL_CONDITIONS_NOT_MET" 5 "USE_SWITCH_OR_PEDAL_TO_ACCELERATE" 6 "DRIVER_ASSISTNCE_SYSTEM_LIMITED_TRAILER_ATTACHED" 7 "DRIVER_ASSISTNCE_SYSTEM_LIMITED_DRIVER_FULL_FACE_NOT_VISIBLE" 11 "LEADING_VEHICLE_IS_DRIVING_AWAY" 12 "STOP_VEHICLE_THEN_TRY_AGAIN" 19 "ACTIVATING_HIGHWAY_DRIVING_PILOT_SYSTEM" 20 "CONTINUING_USE_OF_HIGHWAY_DRIVING_PILOT_WILL_RESULT_IN_DEVIATION_FROM_THE_NAVIGATION_ROUTE" 21 "HIGHWAY_DRIVING_PILOT_SYSTEM_DEACTIVATED_SILENT" 22 "HIGHWAY_DRIVING_PILOT_SYSTEM_NOT_APPLIED" 23 "HIGHWAY_DRIVING_PILOT_CONDITIONS_NOT_MET_SILENT";
VAL_ 353 MUTE 0 "NONE" 1 "MUTED";
VAL_ 353 SOUNDS_1 0 "NONE" 3 "FAST BEEP" 6 "CONSTANT BEEP";
VAL_ 353 SOUNDS_2 0 "NONE" 2 "SINGLE CHIME" 3 "CONSTANT CHIME" 6 "FAST BEEP";
VAL_ 353 SOUNDS_3 0 "NONE" 3 "SOFT CHIME" 5 "SINGLE CHIME";
VAL_ 353 SOUNDS_4 0 "NONE" 2 "DOUBLE CHIME";
VAL_ 353 SETSPEED_HUD 0 "HIDDEN" 1 "GRAY" 2 "GREEN" 3 "WHITE" 5 "CYAN";
VAL_ 353 DISTANCE_LEAD 0 "HIDDEN" 1 "GRAY" 2 "WHITE";
VAL_ 353 DISTANCE_CAR 0 "HIDDEN" 1 "GRAY" 2 "WHITE" 3 "CYAN";
VAL_ 353 DISTANCE_SPACING 0 "HIDDEN" 1 "BLUE" 3 "WHITE" 5 "CYAN";
VAL_ 353 SETSPEED 0 "HIDDEN" 1 "GRAY" 2 "GREEN" 3 "WHITE" 6 "CYAN";
VAL_ 353 HDA_ICON 0 "HIDDEN" 1 "GRAY" 2 "GREEN" 3 "WHITE" 5 "CYAN HDP";
VAL_ 353 SLA_ICON 0 "HIDDEN" 1 "WHITE UP" 2 "WHITE DOWN" 3 "GREEN UP" 4 "GREEN DOWN";
VAL_ 353 NAV_ICON 0 "HIDDEN" 1 "GRAY" 2 "GREEN" 4 "WHITE";
VAL_ 353 LFA_ICON 0 "HIDDEN" 1 "GRAY" 2 "GREEN" 3 "WHITE" 5 "CYAN";
VAL_ 353 LCA_LEFT_ICON 0 "HIDDEN" 1 "GRAY" 2 "GREEN" 4 "WHITE";
VAL_ 353 LCA_RIGHT_ICON 0 "HIDDEN" 1 "GRAY" 2 "GREEN" 4 "WHITE";
VAL_ 353 BACKGROUND 0 "HIDDEN" 1 "BLUE" 3 "ORANGE" 4 "FLASHING ORANGE" 6 "FLASHING RED" 7 "GRAY";
VAL_ 353 DAW_ICON 0 "HIDDEN" 1 "ORANGE";
VAL_ 353 CAR_CIRCLE 0 "HIDDEN" 1 "GRAY" 2 "CYAN";
VAL_ 354 COUNTRY 0 "HIDDEN" 1 "SOUTH_KOREA" 4 "INTL" 5 "JAPAN" 6 "CANADA" 7 "USA" 8 "CHINA" 9 "INTL";
VAL_ 354 SPEEDLIMIT_FLASH 0 "HIDDEN" 1 "ERROR" 2 "NORMAL" 4 "RED";
VAL_ 354 SIGNS 0 "HIDDEN" 1 "PEDESTRIAN_CROSSING" 2 "SCHOOL_CROSSWALK" 8 "STOP" 9 "YIELD" 16 "DO_NOT_PASS" 19 "DO_NOT_ENTER" 24 "ROUNDABOUT" 26 "RIGHT_CURVE_AHEAD" 27 "LEFT_CURVE_AHEAD" 28 "SLIGHT_RIGHT_CURVE_AHEAD" 29 "SLIGHT_LEFT_CURVE_AHEAD";
VAL_ 354 SPEEDLIMIT_WEATHER 0 "HIDDEN" 1 "RAIN" 2 "SNOW" 3 "RAIN+SNOW" 4 "TRAILER";
VAL_ 354 VIBRATE 0 "NONE" 1 "VIBRATE";
VAL_ 354 FF_DETECT 0 "HIDDEN" 1 "GRAY BOX" 2 "WHITE BOX" 3 "GRAY CAR" 4 "WHITE CAR" 5 "GRAY TRUCK" 6 "WHITE TRUCK" 7 "GRAY PERSON" 8 "WHITE PERSON" 9 "GRAY BICYCLE" 10 "WHITE BICYCLE" 11 "GRAY MOTORCYCLE" 12 "WHITE MOTORCYCLE" 13 "DARK CONE" 14 "ORANGE CONE";
VAL_ 354 FF_DETECT_ALT 0 "HIDDEN" 1 "GRAY BOX" 2 "WHITE BOX" 3 "DIM CONE" 4 "ORANGE CONE";
VAL_ 354 LF_DETECT 0 "HIDDEN" 1 "GRAY BOX" 2 "WHITE BOX" 3 "GRAY CAR" 4 "WHITE CAR" 5 "GRAY TRUCK" 6 "WHITE TRUCK" 7 "GRAY PERSON" 8 "WHITE PERSON" 9 "GRAY BICYCLE" 10 "WHITE BICYCLE" 11 "GRAY MOTORCYCLE" 12 "WHITE MOTORCYCLE" 13 "DARK CONE" 14 "ORANGE CONE";
VAL_ 354 RF_DETECT 0 "HIDDEN" 1 "GRAY BOX" 2 "WHITE BOX" 3 "GRAY CAR" 4 "WHITE CAR" 5 "GRAY TRUCK" 6 "WHITE TRUCK" 7 "GRAY PERSON" 8 "WHITE PERSON" 9 "GRAY BICYCLE" 10 "WHITE BICYCLE" 11 "GRAY MOTORCYCLE" 12 "WHITE MOTORCYCLE" 13 "DARK CONE" 14 "ORANGE CONE";
VAL_ 354 LR_DETECT 0 "HIDDEN" 1 "GRAY BOX" 2 "WHITE BOX" 3 "GRAY CAR" 4 "WHITE CAR" 5 "GRAY TRUCK" 6 "WHITE TRUCK" 7 "GRAY PERSON" 8 "WHITE PERSON" 9 "GRAY BICYCLE" 10 "WHITE BICYCLE" 11 "GRAY MOTORCYCLE" 12 "WHITE MOTORCYCLE" 13 "DARK CONE" 14 "ORANGE CONE";
VAL_ 354 RR_DETECT 0 "HIDDEN" 1 "GRAY BOX" 2 "WHITE BOX" 3 "GRAY CAR" 4 "WHITE CAR" 5 "GRAY TRUCK" 6 "WHITE TRUCK" 7 "GRAY PERSON" 8 "WHITE PERSON" 9 "GRAY BICYCLE" 10 "WHITE BICYCLE" 11 "GRAY MOTORCYCLE" 12 "WHITE MOTORCYCLE" 13 "DARK CONE" 14 "ORANGE CONE";
VAL_ 354 FAULT_FSS 0 "HIDDEN" 1 "CHECK_FORWARD_SAFETY_SYSTEM" 2 "FORWARD_SAFETY_SYSTEM_LIMITED_CAMERA_OBSCURED" 3 "FORWARD_SAFETY_SYSTEM_LIMITED_RADAR_BLOCKED";
VAL_ 354 FAULT_FCA 0 "HIDDEN" 1 "CHECK_FORWARD_SIDE_SAFETY_SYSTEM" 2 "FORWARD_SIDE_SAFETY_SYSTEM_LIMITED_CAMERA_OBSCURED" 3 "FORWARD_SIDE_SAFETY_SYSTEM_LIMITED_RADAR_BLOCKED";
VAL_ 354 FAULT_LSS 0 "HIDDEN" 1 "CHECK_LANE_SAFETY_SYSTEM" 2 "LANE_SAFETY_SYSTEM_DISABLED_CAMERA_OBSCURED";
VAL_ 354 FAULT_SLA 0 "HIDDEN" 1 "CHECK_SPEED_LIMIT_SYSTEM" 2 "SPEED_LIMIT_SYSTEM_DISABLED_CAMERA_OBSCURED";
VAL_ 354 FAULT_DAW 0 "HIDDEN" 1 "CHECK_INATTENTIVE_DRIVING_WARNING_SYSTEM" 2 "INATTENTIVE_DRIVING_WARNING_SYSTEM_DISABLED_CAMERA_OBSCURED";
VAL_ 354 FAULT_HBA 0 "HIDDEN" 1 "CHECK_HIGH_BEAM_ASSIST_SYSTEM";
VAL_ 354 FAULT_SCC 0 "HIDDEN" 1 "CHECK_SMART_CRUISE_CONTROL_SYSTEM" 2 "SMART_CRUISE_CONTROL_DISABLED_RADAR_BLOCKED";
VAL_ 354 FAULT_LFA 0 "HIDDEN" 1 "CHECK_LANE_FOLLOWING_SYSTEM_ASSIST_SYSTEM";
VAL_ 354 FAULT_HDA 0 "HIDDEN" 1 "CHECK_HIGHWAY_DRIVING_ASSIST_SYSTEM";
VAL_ 354 FAULT_LCA 0 "HIDDEN" 1 "CHECK_LANE_CHANGE_ASSIST_FUNCTION" 2 "LANE_CHANGE_ASSIST_FUNCTION_DISABLED_CAMERA_OBSCURED" 3 "LANE_CHANGE_ASSIST_FUNCTION_DISABLED_RADAR_BLOCKED";
VAL_ 354 FAULT_HDP 0 "HIDDEN" 1 "CHECK_HIGHWAY_DRIVING_PILOT_SYSTEM" 2 "HIGHWAY_DRIVING_PILOT_DISABLED_CAMERA_OBSCURED" 3 "HIGHWAY_DRIVING_PILOT_DISABLED_RADAR_BLOCKED" 4 "HIGHWAY_DRIVING_PILOT_DISABLED_LIDAR_BLOCKED";
VAL_ 354 FAULT_DAS 0 "HIDDEN" 1 "CHECK_DRIVER_ASSISTANCE_SYSTEM" 2 "DRIVER_ASSISTANCE_SYSTEM_LIMITED_CAMERA_OBSCURED" 3 "DRIVER_ASSISTANCE_SYSTEM_LIMITED_RADAR_BLOCKED" 4 "DRIVER_ASSISTANCE_SYSTEM_LIMITED_CAMERA_OBSCURED_AND_RADAR_BLOCKED";
VAL_ 354 FAULT_ESS 0 "HIDDEN" 1 "CHECK_EMERGENCY_STOPPING_FUNCTION" 2 "EMERGENCY_STOPPING_FUNCTION_DISABLED_CAMERA_OBSCURED" 3 "EMERGENCY_STOPPING_FUNCTION_DISABLED_RADAR_BLOCKED";
VAL_ 362 BLINKER_CONTROL 1 "hazards" 2 "hazards button backlight" 3 "left blinkers" 4 "right blinkers";
VAL_ 373 SCC_OptTyp 0 "SCC is not equipped" 1 "SCC is equipped" 2 "Not used" 3 "Error Indicator";
VAL_ 373 ACCEnable 0 "SCC ready" 1 "SCC temp fault" 2 "SCC permanent fault" 3 "SCC permanent fault, communication issue";
VAL_ 373 SCC_ReqLimSta 0 "No request" 1 "Limited No Limitation" 2 "Acceleration Limited" 3 "Deceleration Limited";
VAL_ 373 ESC_StdStillVal 0 "No stand still detected" 1 "stand still detected" 2 "Not used" 3 "Error Indicator";
VAL_ 373 ESC_DclEnblReq 0 "Disable deceleration control" 1 "Enable deceleration control" 2 "Not used" 3 "Error Indicator";
VAL_ 373 ESC_PrkBrkActvSta 0 "Parking brake is not activated" 1 "Parking brake is activated" 2 "Not used" 3 "Error Indicator";
VAL_ 373 FCA_EquipSta 0 "FCA is not equipped" 1 "FCA is equipped" 2 "Not used" 3 "Error Indicator";
VAL_ 373 FCA_AvlblSta 0 "Available" 1 "Temporarily not available" 2 "Permanently not available" 3 "FCA Communication Error";
VAL_ 416 ACCMode 0 "off" 1 "enabled" 2 "driver_override" 3 "off_maybe_fault" 4 "cancelled";
VAL_ 426 CRUISE_BUTTONS 0 "none" 1 "res_accel" 2 "set_decel" 3 "gap_distance" 4 "pause_resume";
VAL_ 463 CRUISE_BUTTONS 0 "none" 1 "res_accel" 2 "set_decel" 3 "gap_distance" 4 "pause_resume";
VAL_ 463 RIGHT_PADDLE 0 "Not Pulled" 1 "Pulled";
VAL_ 463 LEFT_PADDLE 0 "Not Pulled" 1 "Pulled";
VAL_ 480 HDA_OptUsmSta 0 "Not Applied" 1 "Function Off" 2 "Function On" 3 "Reserved" 4 "Reserved" 5 "Reserved" 6 "Reserved" 7 "Invalid (Fail)";
VAL_ 480 LFA_OptUsmSta 0 "Not Applied" 1 "Function Off" 2 "Function On" 3 "Reserved" 4 "Reserved" 5 "Reserved" 6 "Reserved" 7 "Invalid (Fail)";
VAL_ 480 HDA_CntrlModSta 0 "System Deactive (Default)" 1 "System Ready" 2 "System Active" 3 "Reserved";
VAL_ 480 HDA_InfoPUDis 0 "No pop-up" 1 "system start pop-up" 2 "system auto disengaged pop-up by highway off" 3 "system auto disengaged pop-up" 4 "system Fail pop-up" 5 "Hands-off pop up" 6 "Hands-off pop up w/ sound" 7 "System Automatic off";
VAL_ 480 HDA_AutoSetSpdSta 0 "Auto Set Speed Off" 1 "Auto Set Speed On" 2 "Reserved" 3 "Error indicator";
VAL_ 480 HDA_AutoSetSpdUpdtSta 0 "Auto Set Speed Update Off" 1 "Auto Set Speed Update On" 2 "Reserved" 3 "Error indicator";
VAL_ 480 HDA_LFA_SymSta 0 "Off" 1 "Gray" 2 "Green" 3 "Green blink";
VAL_ 480 HDA_LFA_WrnSnd 0 "Off" 1 "Additional Warning Sound" 2 "Reserved" 3 "Error indicator";
VAL_ 480 HDA_InfoPUDis1 0 "No Pop-up" 1 "System Automatic off (LFA)" 2 "System Automatic off (HDA)" 3 "Reserved" 4 "Reserved" 5 "Reserved" 6 "Not Used" 7 "Error Indicator";
VAL_ 480 HDA_TDMRMDclReq 0 "Not automatically deactivated state of LFA (default)" 1 "Automatically deactivated state of LFA" 2 "Reserved" 3 "Reserved";
VAL_ 490 HDA_MODE2 1 "Lane change icon gray" 2 "lane green + lane change icon green" 3 "lane green + lane change icon green (both blinking)" 4 "lane white + lane change icon white (both blinking rapidly)" 5 "Lane Change Assist system check warning";
VAL_ 490 LANE_LEFT 0 "IDLE" 1 "ON_SOURCE" 2 "ON_TARGET";
VAL_ 490 LANE_RIGHT 0 "IDLE" 1 "ON_SOURCE" 2 "ON_TARGET";
VAL_ 490 LANE_CHANGING 0 "IDLE" 1 "LEFT_CHECK" 3 "LEFT_CHANGING" 2 "RIGHT_CHECK" 4 "RIGHT_CHANGING";
VAL_ 490 LF_DETECT 0 "none" 1 "gray" 2 "white" 3 "white" 4 "hide";
VAL_ 490 RF_DETECT 0 "none" 1 "gray" 2 "white" 3 "white" 4 "hide";
VAL_ 490 LR_DETECT 0 "none" 1 "gray" 2 "white" 3 "white" 4 "hide";
VAL_ 490 RR_DETECT 0 "none" 1 "gray" 2 "white" 3 "white" 4 "hide";
VAL_ 490 AUTOLANECHANGE_MSG 1 "Check surrounding conditions" 2 "Operating conditions not met" 3 "Analyzing driving lane" 4 "Sharp curve ahead" 5 "Current lane is too narrow" 6 "Not an operational section" 7 "Hazard lights are on" 8 "Vehicle speed is too low" 9 "Please hold the steering wheel" 10 "Not an operable lane" 11 "Steering input detected" 12 "Press the OK button to activate lane change assist";
VAL_ 490 LANELINE_CURVATURE_DIRECTION 0 "LEFT" 1 "RIGHT";
VAL_ 676 LEFT_LANE_COLOR 0 "Not Detected" 1 "White" 2 "Yellow" 3 "Blue";
VAL_ 676 RIGHT_LANE_COLOR 0 "Not Detected" 1 "White" 2 "Yellow" 3 "Blue";
VAL_ 676 LEFT_LANE_LINE 0 "Not Detected" 1 "Low Confidence" 2 "Medium Confidence" 3 "High Confidence";
VAL_ 676 RIGHT_LANE_LINE 0 "Not Detected" 1 "Low Confidence" 2 "Medium Confidence" 3 "High Confidence";
VAL_ 736 MSLA_STATUS 0 "disabled" 1 "active" 2 "paused";
VAL_ 866 LEFT_LANE_COLOR 0 "Not Detected" 1 "White" 2 "Yellow" 3 "Blue";
VAL_ 866 RIGHT_LANE_COLOR 0 "Not Detected" 1 "White" 2 "Yellow" 3 "Blue";
VAL_ 866 LEFT_LANE_LINE 0 "Not Detected" 1 "Low Confidence" 2 "Medium Confidence" 3 "High Confidence";
VAL_ 866 RIGHT_LANE_LINE 0 "Not Detected" 1 "Low Confidence" 2 "Medium Confidence" 3 "High Confidence";
VAL_ 1041 DRIVER_DOOR 0 "Closed" 1 "Opened";
VAL_ 1041 PASSENGER_DOOR 0 "Closed" 1 "Opened";
VAL_ 1041 PASSENGER_SEATBELT 0 "Unlatched" 1 "Latched";
VAL_ 1041 DRIVER_SEATBELT 0 "Unlatched" 1 "Latched";
VAL_ 1041 DRIVER_REAR_DOOR 0 "Closed" 1 "Opened";
VAL_ 1041 PASSENGER_REAR_DOOR 0 "Closed" 1 "Opened";
VAL_ 1079 TRAILER_CONNECTED 1 "CONNECTED" 0 "DISCONNECTED";

VAL_ 1144 DRIVE_MODE2 3 "Set Sport" 1 "Set Normal" 2 "Set Eco";
VAL_ 1240 DISTANCE_UNIT 1 "Miles" 0 "Kilometers";

BO_ 884 VEHICLE_POSITION_374: 8 XXX
 SG_ LATITUDE : 0|32@1+ (0.000001,0) [0|85.05112878] "deg" XXX
 SG_ LONGITUDE : 32|32@1+ (0.000001,0) [0|180] "deg" XXX
